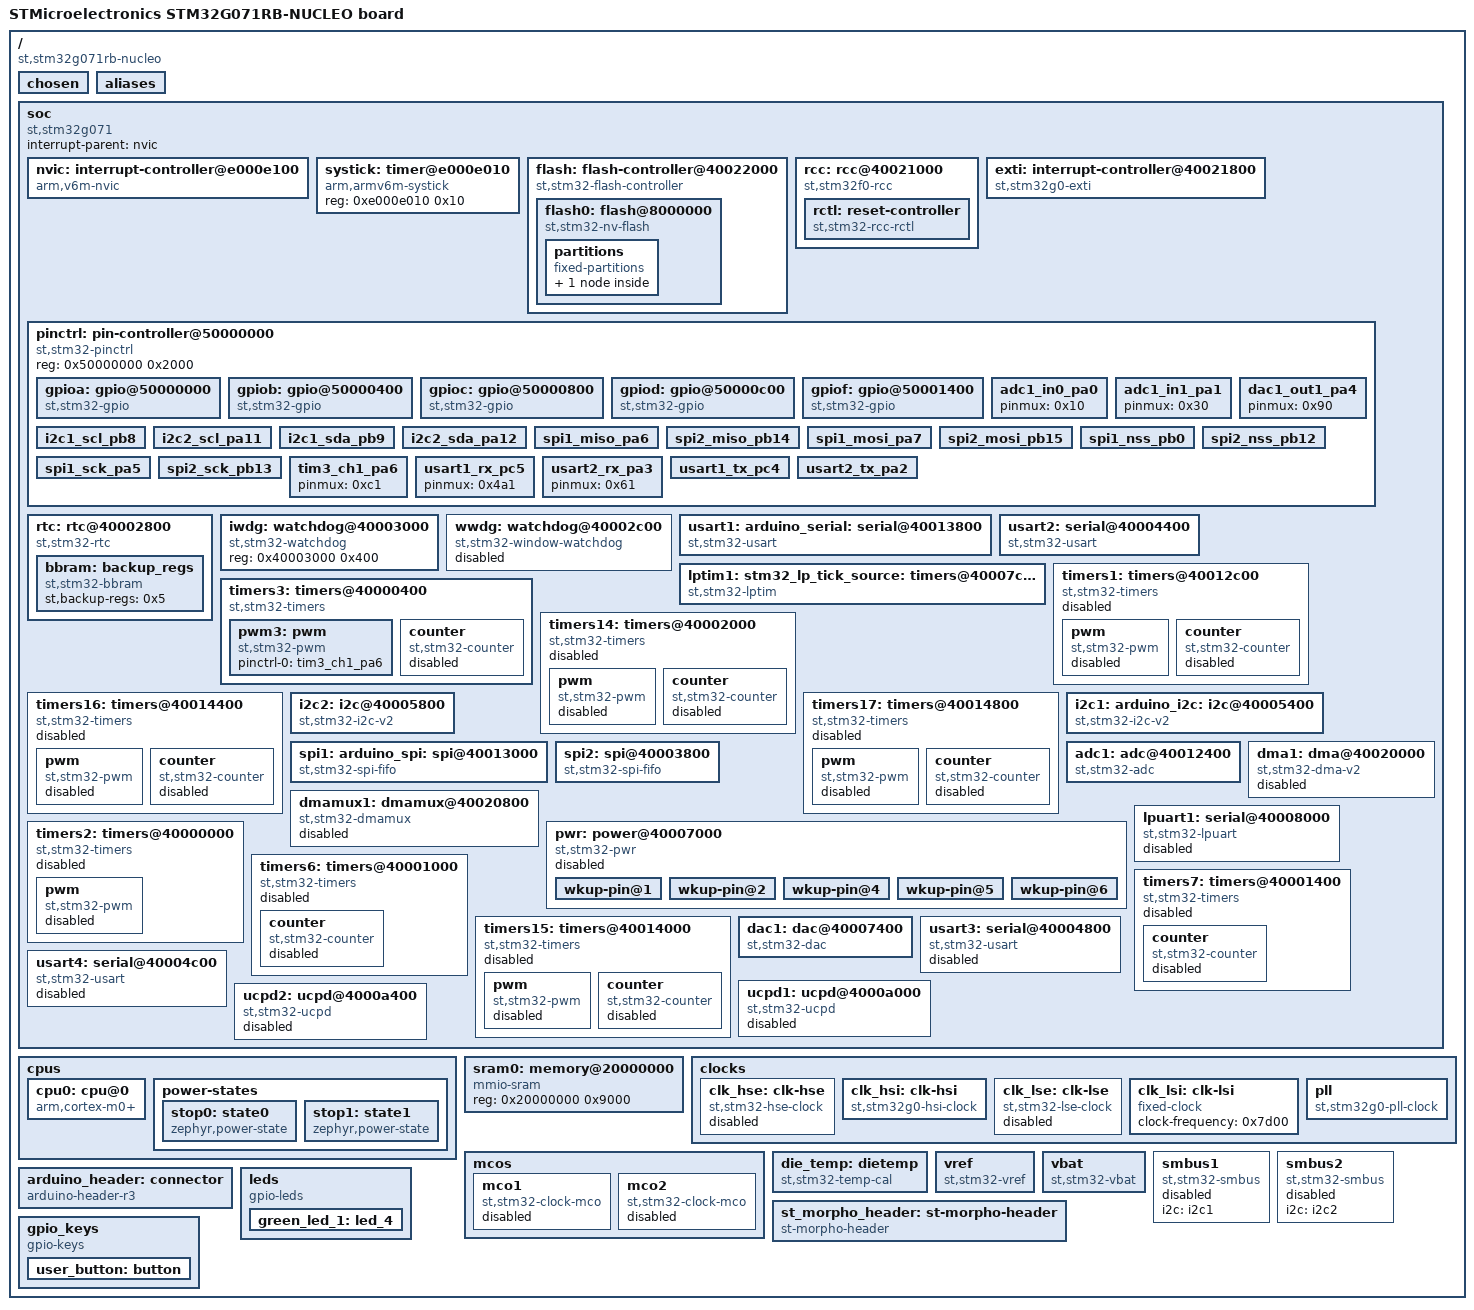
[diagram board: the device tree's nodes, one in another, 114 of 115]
/dts-v1/;

/* node '/' defined in zephyr\dts\common\skeleton.dtsi:9 */
/ {
	#address-cells = < 0x1 >;                              /* in zephyr\dts\common\skeleton.dtsi:10 */
	#size-cells = < 0x1 >;                                 /* in zephyr\dts\common\skeleton.dtsi:11 */
	model = "STMicroelectronics STM32G071RB-NUCLEO board"; /* in zephyr\boards\st\nucleo_g071rb\nucleo_g071rb.dts:16 */
	compatible = "st,stm32g071rb-nucleo";                  /* in zephyr\boards\st\nucleo_g071rb\nucleo_g071rb.dts:17 */

	/* node '/chosen' defined in zephyr\dts\common\skeleton.dtsi:13 */
	chosen {
		zephyr,flash-controller = &flash; /* in zephyr\dts\arm\st\g0\stm32g0.dtsi:26 */
		zephyr,console = &usart2;         /* in zephyr\boards\st\nucleo_g071rb\nucleo_g071rb.dts:20 */
		zephyr,shell-uart = &usart2;      /* in zephyr\boards\st\nucleo_g071rb\nucleo_g071rb.dts:21 */
		zephyr,sram = &sram0;             /* in zephyr\boards\st\nucleo_g071rb\nucleo_g071rb.dts:22 */
		zephyr,flash = &flash0;           /* in zephyr\boards\st\nucleo_g071rb\nucleo_g071rb.dts:23 */
	};

	/* node '/aliases' defined in zephyr\dts\common\skeleton.dtsi:15 */
	aliases {
		led0 = &green_led_1;   /* in zephyr\boards\st\nucleo_g071rb\nucleo_g071rb.dts:46 */
		sw0 = &user_button;    /* in zephyr\boards\st\nucleo_g071rb\nucleo_g071rb.dts:47 */
		watchdog0 = &iwdg;     /* in zephyr\boards\st\nucleo_g071rb\nucleo_g071rb.dts:48 */
		die-temp0 = &die_temp; /* in zephyr\boards\st\nucleo_g071rb\nucleo_g071rb.dts:49 */
		volt-sensor0 = &vref;  /* in zephyr\boards\st\nucleo_g071rb\nucleo_g071rb.dts:50 */
		volt-sensor1 = &vbat;  /* in zephyr\boards\st\nucleo_g071rb\nucleo_g071rb.dts:51 */
	};

	/* node '/soc' defined in zephyr\dts\arm\armv6-m.dtsi:6 */
	soc {
		#address-cells = < 0x1 >;     /* in zephyr\dts\arm\armv6-m.dtsi:7 */
		#size-cells = < 0x1 >;        /* in zephyr\dts\arm\armv6-m.dtsi:8 */
		interrupt-parent = < &nvic >; /* in zephyr\dts\arm\armv6-m.dtsi:10 */
		ranges;                       /* in zephyr\dts\arm\armv6-m.dtsi:11 */
		compatible = "st,stm32g071",
		             "st,stm32g0",
		             "simple-bus";    /* in zephyr\dts\arm\st\g0\stm32g071.dtsi:13 */

		/* node '/soc/interrupt-controller@e000e100' defined in zephyr\dts\arm\armv6-m.dtsi:13 */
		nvic: interrupt-controller@e000e100 {
			#address-cells = < 0x1 >;            /* in zephyr\dts\arm\armv6-m.dtsi:14 */
			compatible = "arm,v6m-nvic";         /* in zephyr\dts\arm\armv6-m.dtsi:15 */
			reg = < 0xe000e100 0xc00 >;          /* in zephyr\dts\arm\armv6-m.dtsi:16 */
			interrupt-controller;                /* in zephyr\dts\arm\armv6-m.dtsi:17 */
			#interrupt-cells = < 0x2 >;          /* in zephyr\dts\arm\armv6-m.dtsi:18 */
			arm,num-irq-priority-bits = < 0x2 >; /* in zephyr\dts\arm\st\g0\stm32g0.dtsi:558 */
			phandle = < 0x1 >;                   /* in zephyr\dts\arm\armv6-m.dtsi:10 */
		};

		/* node '/soc/timer@e000e010' defined in zephyr\dts\arm\armv6-m.dtsi:21 */
		systick: timer@e000e010 {
			compatible = "arm,armv6m-systick"; /* in zephyr\dts\arm\armv6-m.dtsi:22 */
			reg = < 0xe000e010 0x10 >;         /* in zephyr\dts\arm\armv6-m.dtsi:23 */
		};

		/* node '/soc/flash-controller@40022000' defined in zephyr\dts\arm\st\g0\stm32g0.dtsi:111 */
		flash: flash-controller@40022000 {
			compatible = "st,stm32-flash-controller",
			             "st,stm32g0-flash-controller"; /* in zephyr\dts\arm\st\g0\stm32g0.dtsi:112 */
			reg = < 0x40022000 0x400 >;                 /* in zephyr\dts\arm\st\g0\stm32g0.dtsi:113 */
			interrupts = < 0x3 0x0 >;                   /* in zephyr\dts\arm\st\g0\stm32g0.dtsi:114 */
			clocks = < &rcc 0x38 0x100 >;               /* in zephyr\dts\arm\st\g0\stm32g0.dtsi:115 */
			#address-cells = < 0x1 >;                   /* in zephyr\dts\arm\st\g0\stm32g0.dtsi:117 */
			#size-cells = < 0x1 >;                      /* in zephyr\dts\arm\st\g0\stm32g0.dtsi:118 */

			/* node '/soc/flash-controller@40022000/flash@8000000' defined in zephyr\dts\arm\st\g0\stm32g0.dtsi:120 */
			flash0: flash@8000000 {
				compatible = "st,stm32-nv-flash",
				             "soc-nv-flash";      /* in zephyr\dts\arm\st\g0\stm32g0.dtsi:121 */
				write-block-size = < 0x8 >;       /* in zephyr\dts\arm\st\g0\stm32g0.dtsi:123 */
				erase-block-size = < 0x800 >;     /* in zephyr\dts\arm\st\g0\stm32g0.dtsi:124 */
				max-erase-time = < 0x28 >;        /* in zephyr\dts\arm\st\g0\stm32g0.dtsi:126 */
				reg = < 0x8000000 0x20000 >;      /* in zephyr\dts\arm\st\g0\stm32g071Xb.dtsi:19 */

				/* node '/soc/flash-controller@40022000/flash@8000000/partitions' defined in zephyr\boards\st\nucleo_g071rb\nucleo_g071rb.dts:169 */
				partitions {
					compatible = "fixed-partitions"; /* in zephyr\boards\st\nucleo_g071rb\nucleo_g071rb.dts:170 */
					#address-cells = < 0x1 >;        /* in zephyr\boards\st\nucleo_g071rb\nucleo_g071rb.dts:171 */
					#size-cells = < 0x1 >;           /* in zephyr\boards\st\nucleo_g071rb\nucleo_g071rb.dts:172 */

					/* node '/soc/flash-controller@40022000/flash@8000000/partitions/partition@1f000' defined in zephyr\boards\st\nucleo_g071rb\nucleo_g071rb.dts:175 */
					storage_partition: partition@1f000 {
						label = "storage";        /* in zephyr\boards\st\nucleo_g071rb\nucleo_g071rb.dts:176 */
						reg = < 0x1f000 0x1000 >; /* in zephyr\boards\st\nucleo_g071rb\nucleo_g071rb.dts:177 */
					};
				};
			};
		};

		/* node '/soc/rcc@40021000' defined in zephyr\dts\arm\st\g0\stm32g0.dtsi:130 */
		rcc: rcc@40021000 {
			compatible = "st,stm32f0-rcc";   /* in zephyr\dts\arm\st\g0\stm32g0.dtsi:131 */
			#clock-cells = < 0x2 >;          /* in zephyr\dts\arm\st\g0\stm32g0.dtsi:132 */
			reg = < 0x40021000 0x400 >;      /* in zephyr\dts\arm\st\g0\stm32g0.dtsi:133 */
			clocks = < &pll >;               /* in zephyr\boards\st\nucleo_g071rb\nucleo_g071rb.dts:74 */
			clock-frequency = < 0x3d09000 >; /* in zephyr\boards\st\nucleo_g071rb\nucleo_g071rb.dts:75 */
			ahb-prescaler = < 0x1 >;         /* in zephyr\boards\st\nucleo_g071rb\nucleo_g071rb.dts:76 */
			apb1-prescaler = < 0x1 >;        /* in zephyr\boards\st\nucleo_g071rb\nucleo_g071rb.dts:77 */
			phandle = < 0x2 >;               /* in zephyr\dts\arm\st\g0\stm32g0.dtsi:115 */

			/* node '/soc/rcc@40021000/reset-controller' defined in zephyr\dts\arm\st\g0\stm32g0.dtsi:135 */
			rctl: reset-controller {
				compatible = "st,stm32-rcc-rctl"; /* in zephyr\dts\arm\st\g0\stm32g0.dtsi:136 */
				#reset-cells = < 0x1 >;           /* in zephyr\dts\arm\st\g0\stm32g0.dtsi:137 */
				phandle = < 0x4 >;                /* in zephyr\dts\arm\st\g0\stm32g0.dtsi:242 */
			};
		};

		/* node '/soc/interrupt-controller@40021800' defined in zephyr\dts\arm\st\g0\stm32g0.dtsi:141 */
		exti: interrupt-controller@40021800 {
			compatible = "st,stm32g0-exti",
			             "st,stm32-exti";   /* in zephyr\dts\arm\st\g0\stm32g0.dtsi:142 */
			interrupt-controller;           /* in zephyr\dts\arm\st\g0\stm32g0.dtsi:143 */
			#interrupt-cells = < 0x1 >;     /* in zephyr\dts\arm\st\g0\stm32g0.dtsi:144 */
			#address-cells = < 0x1 >;       /* in zephyr\dts\arm\st\g0\stm32g0.dtsi:145 */
			reg = < 0x40021800 0x400 >;     /* in zephyr\dts\arm\st\g0\stm32g0.dtsi:146 */
			clocks = < &rcc 0x40 0x1 >;     /* in zephyr\dts\arm\st\g0\stm32g0.dtsi:147 */
			num-lines = < 0x20 >;           /* in zephyr\dts\arm\st\g0\stm32g0.dtsi:148 */
			interrupts = < 0x5 0x0 >,
			             < 0x6 0x0 >,
			             < 0x7 0x0 >;       /* in zephyr\dts\arm\st\g0\stm32g0.dtsi:149 */
			interrupt-names = "line0-1",
			                  "line2-3",
			                  "line4-15";   /* in zephyr\dts\arm\st\g0\stm32g0.dtsi:150 */
			line-ranges = < 0x0 0x2 >,
			              < 0x2 0x2 >,
			              < 0x4 0xc >;      /* in zephyr\dts\arm\st\g0\stm32g0.dtsi:151 */
		};

		/* node '/soc/pin-controller@50000000' defined in zephyr\dts\arm\st\g0\stm32g0.dtsi:154 */
		pinctrl: pin-controller@50000000 {
			compatible = "st,stm32-pinctrl"; /* in zephyr\dts\arm\st\g0\stm32g0.dtsi:155 */
			#address-cells = < 0x1 >;        /* in zephyr\dts\arm\st\g0\stm32g0.dtsi:156 */
			#size-cells = < 0x1 >;           /* in zephyr\dts\arm\st\g0\stm32g0.dtsi:157 */
			reg = < 0x50000000 0x2000 >;     /* in zephyr\dts\arm\st\g0\stm32g0.dtsi:158 */

			/* node '/soc/pin-controller@50000000/gpio@50000000' defined in zephyr\dts\arm\st\g0\stm32g0.dtsi:160 */
			gpioa: gpio@50000000 {
				compatible = "st,stm32-gpio"; /* in zephyr\dts\arm\st\g0\stm32g0.dtsi:161 */
				gpio-controller;              /* in zephyr\dts\arm\st\g0\stm32g0.dtsi:162 */
				#gpio-cells = < 0x2 >;        /* in zephyr\dts\arm\st\g0\stm32g0.dtsi:163 */
				reg = < 0x50000000 0x400 >;   /* in zephyr\dts\arm\st\g0\stm32g0.dtsi:164 */
				clocks = < &rcc 0x34 0x1 >;   /* in zephyr\dts\arm\st\g0\stm32g0.dtsi:165 */
				phandle = < 0x18 >;           /* in zephyr\dts\arm\st\g0\stm32g0.dtsi:486 */
			};

			/* node '/soc/pin-controller@50000000/gpio@50000400' defined in zephyr\dts\arm\st\g0\stm32g0.dtsi:168 */
			gpiob: gpio@50000400 {
				compatible = "st,stm32-gpio"; /* in zephyr\dts\arm\st\g0\stm32g0.dtsi:169 */
				gpio-controller;              /* in zephyr\dts\arm\st\g0\stm32g0.dtsi:170 */
				#gpio-cells = < 0x2 >;        /* in zephyr\dts\arm\st\g0\stm32g0.dtsi:171 */
				reg = < 0x50000400 0x400 >;   /* in zephyr\dts\arm\st\g0\stm32g0.dtsi:172 */
				clocks = < &rcc 0x34 0x2 >;   /* in zephyr\dts\arm\st\g0\stm32g0.dtsi:173 */
				phandle = < 0x1a >;           /* in zephyr\dts\arm\st\g0\stm32g0.dtsi:509 */
			};

			/* node '/soc/pin-controller@50000000/gpio@50000800' defined in zephyr\dts\arm\st\g0\stm32g0.dtsi:176 */
			gpioc: gpio@50000800 {
				compatible = "st,stm32-gpio"; /* in zephyr\dts\arm\st\g0\stm32g0.dtsi:177 */
				gpio-controller;              /* in zephyr\dts\arm\st\g0\stm32g0.dtsi:178 */
				#gpio-cells = < 0x2 >;        /* in zephyr\dts\arm\st\g0\stm32g0.dtsi:179 */
				reg = < 0x50000800 0x400 >;   /* in zephyr\dts\arm\st\g0\stm32g0.dtsi:180 */
				clocks = < &rcc 0x34 0x4 >;   /* in zephyr\dts\arm\st\g0\stm32g0.dtsi:181 */
				phandle = < 0x19 >;           /* in zephyr\dts\arm\st\g0\stm32g0.dtsi:491 */
			};

			/* node '/soc/pin-controller@50000000/gpio@50000c00' defined in zephyr\dts\arm\st\g0\stm32g0.dtsi:184 */
			gpiod: gpio@50000c00 {
				compatible = "st,stm32-gpio"; /* in zephyr\dts\arm\st\g0\stm32g0.dtsi:185 */
				gpio-controller;              /* in zephyr\dts\arm\st\g0\stm32g0.dtsi:186 */
				#gpio-cells = < 0x2 >;        /* in zephyr\dts\arm\st\g0\stm32g0.dtsi:187 */
				reg = < 0x50000c00 0x400 >;   /* in zephyr\dts\arm\st\g0\stm32g0.dtsi:188 */
				clocks = < &rcc 0x34 0x8 >;   /* in zephyr\dts\arm\st\g0\stm32g0.dtsi:189 */
				phandle = < 0x22 >;           /* in zephyr\boards\st\nucleo_g071rb\st_morpho_connector.dtsi:15 */
			};

			/* node '/soc/pin-controller@50000000/gpio@50001400' defined in zephyr\dts\arm\st\g0\stm32g0.dtsi:192 */
			gpiof: gpio@50001400 {
				compatible = "st,stm32-gpio"; /* in zephyr\dts\arm\st\g0\stm32g0.dtsi:193 */
				gpio-controller;              /* in zephyr\dts\arm\st\g0\stm32g0.dtsi:194 */
				#gpio-cells = < 0x2 >;        /* in zephyr\dts\arm\st\g0\stm32g0.dtsi:195 */
				reg = < 0x50001400 0x400 >;   /* in zephyr\dts\arm\st\g0\stm32g0.dtsi:196 */
				clocks = < &rcc 0x34 0x20 >;  /* in zephyr\dts\arm\st\g0\stm32g0.dtsi:197 */
				phandle = < 0x23 >;           /* in zephyr\boards\st\nucleo_g071rb\st_morpho_connector.dtsi:15 */
			};

			/* node '/soc/pin-controller@50000000/adc1_in0_pa0' defined in modules\hal\stm32\dts\st\g0\stm32g071r(6-8-b)tx-pinctrl.dtsi:15 */
			adc1_in0_pa0: adc1_in0_pa0 {
				pinmux = < 0x10 >;  /* in modules\hal\stm32\dts\st\g0\stm32g071r(6-8-b)tx-pinctrl.dtsi:16 */
				phandle = < 0x16 >; /* in zephyr\boards\st\nucleo_g071rb\nucleo_g071rb.dts:150 */
			};

			/* node '/soc/pin-controller@50000000/adc1_in1_pa1' defined in modules\hal\stm32\dts\st\g0\stm32g071r(6-8-b)tx-pinctrl.dtsi:19 */
			adc1_in1_pa1: adc1_in1_pa1 {
				pinmux = < 0x30 >;  /* in modules\hal\stm32\dts\st\g0\stm32g071r(6-8-b)tx-pinctrl.dtsi:20 */
				phandle = < 0x17 >; /* in zephyr\boards\st\nucleo_g071rb\nucleo_g071rb.dts:150 */
			};

			/* node '/soc/pin-controller@50000000/dac1_out1_pa4' defined in modules\hal\stm32\dts\st\g0\stm32g071r(6-8-b)tx-pinctrl.dtsi:415 */
			dac1_out1_pa4: dac1_out1_pa4 {
				pinmux = < 0x90 >;  /* in modules\hal\stm32\dts\st\g0\stm32g071r(6-8-b)tx-pinctrl.dtsi:416 */
				phandle = < 0x1b >; /* in zephyr\boards\st\nucleo_g071rb\nucleo_g071rb.dts:160 */
			};

			/* node '/soc/pin-controller@50000000/i2c1_scl_pb8' defined in modules\hal\stm32\dts\st\g0\stm32g071r(6-8-b)tx-pinctrl.dtsi:437 */
			i2c1_scl_pb8: i2c1_scl_pb8 {
				pinmux = < 0x306 >; /* in modules\hal\stm32\dts\st\g0\stm32g071r(6-8-b)tx-pinctrl.dtsi:438 */
				bias-pull-up;       /* in modules\hal\stm32\dts\st\g0\stm32g071r(6-8-b)tx-pinctrl.dtsi:439 */
				drive-open-drain;   /* in modules\hal\stm32\dts\st\g0\stm32g071r(6-8-b)tx-pinctrl.dtsi:440 */
				phandle = < 0xa >;  /* in zephyr\boards\st\nucleo_g071rb\nucleo_g071rb.dts:120 */
			};

			/* node '/soc/pin-controller@50000000/i2c2_scl_pa11' defined in modules\hal\stm32\dts\st\g0\stm32g071r(6-8-b)tx-pinctrl.dtsi:443 */
			i2c2_scl_pa11: i2c2_scl_pa11 {
				pinmux = < 0x166 >; /* in modules\hal\stm32\dts\st\g0\stm32g071r(6-8-b)tx-pinctrl.dtsi:444 */
				bias-pull-up;       /* in modules\hal\stm32\dts\st\g0\stm32g071r(6-8-b)tx-pinctrl.dtsi:445 */
				drive-open-drain;   /* in modules\hal\stm32\dts\st\g0\stm32g071r(6-8-b)tx-pinctrl.dtsi:446 */
				phandle = < 0xc >;  /* in zephyr\boards\st\nucleo_g071rb\nucleo_g071rb.dts:127 */
			};

			/* node '/soc/pin-controller@50000000/i2c1_sda_pb9' defined in modules\hal\stm32\dts\st\g0\stm32g071r(6-8-b)tx-pinctrl.dtsi:475 */
			i2c1_sda_pb9: i2c1_sda_pb9 {
				pinmux = < 0x326 >; /* in modules\hal\stm32\dts\st\g0\stm32g071r(6-8-b)tx-pinctrl.dtsi:476 */
				bias-pull-up;       /* in modules\hal\stm32\dts\st\g0\stm32g071r(6-8-b)tx-pinctrl.dtsi:477 */
				drive-open-drain;   /* in modules\hal\stm32\dts\st\g0\stm32g071r(6-8-b)tx-pinctrl.dtsi:478 */
				phandle = < 0xb >;  /* in zephyr\boards\st\nucleo_g071rb\nucleo_g071rb.dts:120 */
			};

			/* node '/soc/pin-controller@50000000/i2c2_sda_pa12' defined in modules\hal\stm32\dts\st\g0\stm32g071r(6-8-b)tx-pinctrl.dtsi:481 */
			i2c2_sda_pa12: i2c2_sda_pa12 {
				pinmux = < 0x186 >; /* in modules\hal\stm32\dts\st\g0\stm32g071r(6-8-b)tx-pinctrl.dtsi:482 */
				bias-pull-up;       /* in modules\hal\stm32\dts\st\g0\stm32g071r(6-8-b)tx-pinctrl.dtsi:483 */
				drive-open-drain;   /* in modules\hal\stm32\dts\st\g0\stm32g071r(6-8-b)tx-pinctrl.dtsi:484 */
				phandle = < 0xd >;  /* in zephyr\boards\st\nucleo_g071rb\nucleo_g071rb.dts:127 */
			};

			/* node '/soc/pin-controller@50000000/spi1_miso_pa6' defined in modules\hal\stm32\dts\st\g0\stm32g071r(6-8-b)tx-pinctrl.dtsi:624 */
			spi1_miso_pa6: spi1_miso_pa6 {
				pinmux = < 0xc0 >;  /* in modules\hal\stm32\dts\st\g0\stm32g071r(6-8-b)tx-pinctrl.dtsi:625 */
				bias-pull-down;     /* in modules\hal\stm32\dts\st\g0\stm32g071r(6-8-b)tx-pinctrl.dtsi:626 */
				phandle = < 0x10 >; /* in zephyr\boards\st\nucleo_g071rb\nucleo_g071rb.dts:134 */
			};

			/* node '/soc/pin-controller@50000000/spi2_miso_pb14' defined in modules\hal\stm32\dts\st\g0\stm32g071r(6-8-b)tx-pinctrl.dtsi:664 */
			spi2_miso_pb14: spi2_miso_pb14 {
				pinmux = < 0x3c0 >; /* in modules\hal\stm32\dts\st\g0\stm32g071r(6-8-b)tx-pinctrl.dtsi:665 */
				bias-pull-down;     /* in modules\hal\stm32\dts\st\g0\stm32g071r(6-8-b)tx-pinctrl.dtsi:666 */
				phandle = < 0x14 >; /* in zephyr\boards\st\nucleo_g071rb\nucleo_g071rb.dts:141 */
			};

			/* node '/soc/pin-controller@50000000/spi1_mosi_pa7' defined in modules\hal\stm32\dts\st\g0\stm32g071r(6-8-b)tx-pinctrl.dtsi:686 */
			spi1_mosi_pa7: spi1_mosi_pa7 {
				pinmux = < 0xe0 >;  /* in modules\hal\stm32\dts\st\g0\stm32g071r(6-8-b)tx-pinctrl.dtsi:687 */
				bias-pull-down;     /* in modules\hal\stm32\dts\st\g0\stm32g071r(6-8-b)tx-pinctrl.dtsi:688 */
				phandle = < 0x11 >; /* in zephyr\boards\st\nucleo_g071rb\nucleo_g071rb.dts:134 */
			};

			/* node '/soc/pin-controller@50000000/spi2_mosi_pb15' defined in modules\hal\stm32\dts\st\g0\stm32g071r(6-8-b)tx-pinctrl.dtsi:726 */
			spi2_mosi_pb15: spi2_mosi_pb15 {
				pinmux = < 0x3e0 >; /* in modules\hal\stm32\dts\st\g0\stm32g071r(6-8-b)tx-pinctrl.dtsi:727 */
				bias-pull-down;     /* in modules\hal\stm32\dts\st\g0\stm32g071r(6-8-b)tx-pinctrl.dtsi:728 */
				phandle = < 0x15 >; /* in zephyr\boards\st\nucleo_g071rb\nucleo_g071rb.dts:141 */
			};

			/* node '/soc/pin-controller@50000000/spi1_nss_pb0' defined in modules\hal\stm32\dts\st\g0\stm32g071r(6-8-b)tx-pinctrl.dtsi:753 */
			spi1_nss_pb0: spi1_nss_pb0 {
				pinmux = < 0x200 >; /* in modules\hal\stm32\dts\st\g0\stm32g071r(6-8-b)tx-pinctrl.dtsi:754 */
				bias-pull-up;       /* in modules\hal\stm32\dts\st\g0\stm32g071r(6-8-b)tx-pinctrl.dtsi:755 */
				phandle = < 0xe >;  /* in zephyr\boards\st\nucleo_g071rb\nucleo_g071rb.dts:134 */
			};

			/* node '/soc/pin-controller@50000000/spi2_nss_pb12' defined in modules\hal\stm32\dts\st\g0\stm32g071r(6-8-b)tx-pinctrl.dtsi:773 */
			spi2_nss_pb12: spi2_nss_pb12 {
				pinmux = < 0x380 >; /* in modules\hal\stm32\dts\st\g0\stm32g071r(6-8-b)tx-pinctrl.dtsi:774 */
				bias-pull-up;       /* in modules\hal\stm32\dts\st\g0\stm32g071r(6-8-b)tx-pinctrl.dtsi:775 */
				phandle = < 0x12 >; /* in zephyr\boards\st\nucleo_g071rb\nucleo_g071rb.dts:141 */
			};

			/* node '/soc/pin-controller@50000000/spi1_sck_pa5' defined in modules\hal\stm32\dts\st\g0\stm32g071r(6-8-b)tx-pinctrl.dtsi:791 */
			spi1_sck_pa5: spi1_sck_pa5 {
				pinmux = < 0xa0 >;             /* in modules\hal\stm32\dts\st\g0\stm32g071r(6-8-b)tx-pinctrl.dtsi:792 */
				bias-pull-down;                /* in modules\hal\stm32\dts\st\g0\stm32g071r(6-8-b)tx-pinctrl.dtsi:793 */
				slew-rate = "very-high-speed"; /* in modules\hal\stm32\dts\st\g0\stm32g071r(6-8-b)tx-pinctrl.dtsi:794 */
				phandle = < 0xf >;             /* in zephyr\boards\st\nucleo_g071rb\nucleo_g071rb.dts:134 */
			};

			/* node '/soc/pin-controller@50000000/spi2_sck_pb13' defined in modules\hal\stm32\dts\st\g0\stm32g071r(6-8-b)tx-pinctrl.dtsi:827 */
			spi2_sck_pb13: spi2_sck_pb13 {
				pinmux = < 0x3a0 >;            /* in modules\hal\stm32\dts\st\g0\stm32g071r(6-8-b)tx-pinctrl.dtsi:828 */
				bias-pull-down;                /* in modules\hal\stm32\dts\st\g0\stm32g071r(6-8-b)tx-pinctrl.dtsi:829 */
				slew-rate = "very-high-speed"; /* in modules\hal\stm32\dts\st\g0\stm32g071r(6-8-b)tx-pinctrl.dtsi:830 */
				phandle = < 0x13 >;            /* in zephyr\boards\st\nucleo_g071rb\nucleo_g071rb.dts:141 */
			};

			/* node '/soc/pin-controller@50000000/tim3_ch1_pa6' defined in modules\hal\stm32\dts\st\g0\stm32g071r(6-8-b)tx-pinctrl.dtsi:969 */
			tim3_ch1_pa6: tim3_ch1_pa6 {
				pinmux = < 0xc1 >; /* in modules\hal\stm32\dts\st\g0\stm32g071r(6-8-b)tx-pinctrl.dtsi:970 */
				phandle = < 0x9 >; /* in zephyr\boards\st\nucleo_g071rb\nucleo_g071rb.dts:114 */
			};

			/* node '/soc/pin-controller@50000000/usart1_rx_pc5' defined in modules\hal\stm32\dts\st\g0\stm32g071r(6-8-b)tx-pinctrl.dtsi:1284 */
			usart1_rx_pc5: usart1_rx_pc5 {
				pinmux = < 0x4a1 >; /* in modules\hal\stm32\dts\st\g0\stm32g071r(6-8-b)tx-pinctrl.dtsi:1285 */
				phandle = < 0x6 >;  /* in zephyr\boards\st\nucleo_g071rb\nucleo_g071rb.dts:81 */
			};

			/* node '/soc/pin-controller@50000000/usart2_rx_pa3' defined in modules\hal\stm32\dts\st\g0\stm32g071r(6-8-b)tx-pinctrl.dtsi:1288 */
			usart2_rx_pa3: usart2_rx_pa3 {
				pinmux = < 0x61 >; /* in modules\hal\stm32\dts\st\g0\stm32g071r(6-8-b)tx-pinctrl.dtsi:1289 */
				phandle = < 0x8 >; /* in zephyr\boards\st\nucleo_g071rb\nucleo_g071rb.dts:88 */
			};

			/* node '/soc/pin-controller@50000000/usart1_tx_pc4' defined in modules\hal\stm32\dts\st\g0\stm32g071r(6-8-b)tx-pinctrl.dtsi:1359 */
			usart1_tx_pc4: usart1_tx_pc4 {
				pinmux = < 0x481 >; /* in modules\hal\stm32\dts\st\g0\stm32g071r(6-8-b)tx-pinctrl.dtsi:1360 */
				bias-pull-up;       /* in modules\hal\stm32\dts\st\g0\stm32g071r(6-8-b)tx-pinctrl.dtsi:1361 */
				phandle = < 0x5 >;  /* in zephyr\boards\st\nucleo_g071rb\nucleo_g071rb.dts:81 */
			};

			/* node '/soc/pin-controller@50000000/usart2_tx_pa2' defined in modules\hal\stm32\dts\st\g0\stm32g071r(6-8-b)tx-pinctrl.dtsi:1364 */
			usart2_tx_pa2: usart2_tx_pa2 {
				pinmux = < 0x41 >; /* in modules\hal\stm32\dts\st\g0\stm32g071r(6-8-b)tx-pinctrl.dtsi:1365 */
				bias-pull-up;      /* in modules\hal\stm32\dts\st\g0\stm32g071r(6-8-b)tx-pinctrl.dtsi:1366 */
				phandle = < 0x7 >; /* in zephyr\boards\st\nucleo_g071rb\nucleo_g071rb.dts:88 */
			};
		};

		/* node '/soc/rtc@40002800' defined in zephyr\dts\arm\st\g0\stm32g0.dtsi:201 */
		rtc: rtc@40002800 {
			compatible = "st,stm32-rtc";      /* in zephyr\dts\arm\st\g0\stm32g0.dtsi:202 */
			reg = < 0x40002800 0x400 >;       /* in zephyr\dts\arm\st\g0\stm32g0.dtsi:203 */
			interrupts = < 0x2 0x0 >;         /* in zephyr\dts\arm\st\g0\stm32g0.dtsi:204 */
			prescaler = < 0x8000 >;           /* in zephyr\dts\arm\st\g0\stm32g0.dtsi:206 */
			alarms-count = < 0x2 >;           /* in zephyr\dts\arm\st\g0\stm32g0.dtsi:207 */
			alrm-exti-line = < 0x13 >;        /* in zephyr\dts\arm\st\g0\stm32g0.dtsi:208 */
			clocks = < &rcc 0x3c 0x400 >,
			         < &rcc 0x3 0x10c8005c >; /* in zephyr\boards\st\nucleo_g071rb\nucleo_g071rb.dts:95 */
			status = "okay";                  /* in zephyr\boards\st\nucleo_g071rb\nucleo_g071rb.dts:97 */

			/* node '/soc/rtc@40002800/backup_regs' defined in zephyr\dts\arm\st\g0\stm32g0.dtsi:217 */
			bbram: backup_regs {
				compatible = "st,stm32-bbram"; /* in zephyr\dts\arm\st\g0\stm32g0.dtsi:218 */
				st,backup-regs = < 0x5 >;      /* in zephyr\dts\arm\st\g0\stm32g0.dtsi:219 */
				status = "okay";               /* in zephyr\boards\st\nucleo_g071rb\nucleo_g071rb.dts:100 */
			};
		};

		/* node '/soc/watchdog@40003000' defined in zephyr\dts\arm\st\g0\stm32g0.dtsi:224 */
		iwdg: watchdog@40003000 {
			compatible = "st,stm32-watchdog"; /* in zephyr\dts\arm\st\g0\stm32g0.dtsi:225 */
			reg = < 0x40003000 0x400 >;       /* in zephyr\dts\arm\st\g0\stm32g0.dtsi:226 */
			status = "okay";                  /* in zephyr\boards\st\nucleo_g071rb\nucleo_g071rb.dts:105 */
		};

		/* node '/soc/watchdog@40002c00' defined in zephyr\dts\arm\st\g0\stm32g0.dtsi:230 */
		wwdg: watchdog@40002c00 {
			compatible = "st,stm32-window-watchdog"; /* in zephyr\dts\arm\st\g0\stm32g0.dtsi:231 */
			reg = < 0x40002c00 0x400 >;              /* in zephyr\dts\arm\st\g0\stm32g0.dtsi:232 */
			clocks = < &rcc 0x3c 0x800 >;            /* in zephyr\dts\arm\st\g0\stm32g0.dtsi:233 */
			interrupts = < 0x0 0x2 >;                /* in zephyr\dts\arm\st\g0\stm32g0.dtsi:234 */
			status = "disabled";                     /* in zephyr\dts\arm\st\g0\stm32g0.dtsi:235 */
		};

		/* node '/soc/serial@40013800' defined in zephyr\dts\arm\st\g0\stm32g0.dtsi:238 */
		usart1: arduino_serial: serial@40013800 {
			compatible = "st,stm32-usart",
			             "st,stm32-uart";                  /* in zephyr\dts\arm\st\g0\stm32g0.dtsi:239 */
			reg = < 0x40013800 0x400 >;                    /* in zephyr\dts\arm\st\g0\stm32g0.dtsi:240 */
			clocks = < &rcc 0x40 0x4000 >;                 /* in zephyr\dts\arm\st\g0\stm32g0.dtsi:241 */
			resets = < &rctl 0x60e >;                      /* in zephyr\dts\arm\st\g0\stm32g0.dtsi:242 */
			interrupts = < 0x1b 0x0 >;                     /* in zephyr\dts\arm\st\g0\stm32g0.dtsi:243 */
			pinctrl-0 = < &usart1_tx_pc4 &usart1_rx_pc5 >; /* in zephyr\boards\st\nucleo_g071rb\nucleo_g071rb.dts:81 */
			pinctrl-names = "default";                     /* in zephyr\boards\st\nucleo_g071rb\nucleo_g071rb.dts:82 */
			current-speed = < 0x1c200 >;                   /* in zephyr\boards\st\nucleo_g071rb\nucleo_g071rb.dts:83 */
			status = "okay";                               /* in zephyr\boards\st\nucleo_g071rb\nucleo_g071rb.dts:84 */
		};

		/* node '/soc/serial@40004400' defined in zephyr\dts\arm\st\g0\stm32g0.dtsi:247 */
		usart2: serial@40004400 {
			compatible = "st,stm32-usart",
			             "st,stm32-uart";                  /* in zephyr\dts\arm\st\g0\stm32g0.dtsi:248 */
			reg = < 0x40004400 0x400 >;                    /* in zephyr\dts\arm\st\g0\stm32g0.dtsi:249 */
			clocks = < &rcc 0x3c 0x20000 >;                /* in zephyr\dts\arm\st\g0\stm32g0.dtsi:250 */
			resets = < &rctl 0x591 >;                      /* in zephyr\dts\arm\st\g0\stm32g0.dtsi:251 */
			interrupts = < 0x1c 0x0 >;                     /* in zephyr\dts\arm\st\g0\stm32g0.dtsi:252 */
			pinctrl-0 = < &usart2_tx_pa2 &usart2_rx_pa3 >; /* in zephyr\boards\st\nucleo_g071rb\nucleo_g071rb.dts:88 */
			pinctrl-names = "default";                     /* in zephyr\boards\st\nucleo_g071rb\nucleo_g071rb.dts:89 */
			current-speed = < 0x1c200 >;                   /* in zephyr\boards\st\nucleo_g071rb\nucleo_g071rb.dts:90 */
			status = "okay";                               /* in zephyr\boards\st\nucleo_g071rb\nucleo_g071rb.dts:91 */
		};

		/* node '/soc/timers@40007c00' defined in zephyr\dts\arm\st\g0\stm32g0.dtsi:256 */
		lptim1: stm32_lp_tick_source: timers@40007c00 {
			compatible = "st,stm32-lptim";     /* in zephyr\dts\arm\st\g0\stm32g0.dtsi:257 */
			#address-cells = < 0x1 >;          /* in zephyr\dts\arm\st\g0\stm32g0.dtsi:259 */
			#size-cells = < 0x0 >;             /* in zephyr\dts\arm\st\g0\stm32g0.dtsi:260 */
			reg = < 0x40007c00 0x400 >;        /* in zephyr\dts\arm\st\g0\stm32g0.dtsi:261 */
			interrupts = < 0x11 0x1 >;         /* in zephyr\dts\arm\st\g0\stm32g0.dtsi:262 */
			interrupt-names = "wakeup";        /* in zephyr\dts\arm\st\g0\stm32g0.dtsi:263 */
			clocks = < &rcc 0x3c 0x80000000 >,
			         < &rcc 0x3 0x8d20054 >;   /* in zephyr\boards\st\nucleo_g071rb\nucleo_g071rb.dts:183 */
			status = "okay";                   /* in zephyr\boards\st\nucleo_g071rb\nucleo_g071rb.dts:185 */
		};

		/* node '/soc/timers@40012c00' defined in zephyr\dts\arm\st\g0\stm32g0.dtsi:267 */
		timers1: timers@40012c00 {
			compatible = "st,stm32-timers";     /* in zephyr\dts\arm\st\g0\stm32g0.dtsi:268 */
			reg = < 0x40012c00 0x400 >;         /* in zephyr\dts\arm\st\g0\stm32g0.dtsi:269 */
			resets = < &rctl 0x60b >;           /* in zephyr\dts\arm\st\g0\stm32g0.dtsi:272 */
			interrupts = < 0xd 0x0 >,
			             < 0xe 0x0 >;           /* in zephyr\dts\arm\st\g0\stm32g0.dtsi:273 */
			interrupt-names = "brk_up_trg_com",
			                  "cc";             /* in zephyr\dts\arm\st\g0\stm32g0.dtsi:274 */
			st,prescaler = < 0x0 >;             /* in zephyr\dts\arm\st\g0\stm32g0.dtsi:275 */
			status = "disabled";                /* in zephyr\dts\arm\st\g0\stm32g0.dtsi:276 */
			clocks = < &rcc 0x40 0x800 >,
			         < &rcc 0x9 0x560054 >;     /* in zephyr\dts\arm\st\g0\stm32g031.dtsi:24 */

			/* node '/soc/timers@40012c00/pwm' defined in zephyr\dts\arm\st\g0\stm32g0.dtsi:278 */
			pwm {
				compatible = "st,stm32-pwm"; /* in zephyr\dts\arm\st\g0\stm32g0.dtsi:279 */
				status = "disabled";         /* in zephyr\dts\arm\st\g0\stm32g0.dtsi:280 */
				#pwm-cells = < 0x3 >;        /* in zephyr\dts\arm\st\g0\stm32g0.dtsi:281 */
			};

			/* node '/soc/timers@40012c00/counter' defined in zephyr\dts\arm\st\g0\stm32g0.dtsi:284 */
			counter {
				compatible = "st,stm32-counter"; /* in zephyr\dts\arm\st\g0\stm32g0.dtsi:285 */
				status = "disabled";             /* in zephyr\dts\arm\st\g0\stm32g0.dtsi:286 */
			};
		};

		/* node '/soc/timers@40000400' defined in zephyr\dts\arm\st\g0\stm32g0.dtsi:290 */
		timers3: timers@40000400 {
			compatible = "st,stm32-timers"; /* in zephyr\dts\arm\st\g0\stm32g0.dtsi:291 */
			reg = < 0x40000400 0x400 >;     /* in zephyr\dts\arm\st\g0\stm32g0.dtsi:292 */
			clocks = < &rcc 0x3c 0x2 >,
			         < &rcc 0x9 0xff >;     /* in zephyr\dts\arm\st\g0\stm32g0.dtsi:293 */
			resets = < &rctl 0x581 >;       /* in zephyr\dts\arm\st\g0\stm32g0.dtsi:295 */
			interrupts = < 0x10 0x0 >;      /* in zephyr\dts\arm\st\g0\stm32g0.dtsi:296 */
			interrupt-names = "global";     /* in zephyr\dts\arm\st\g0\stm32g0.dtsi:297 */
			st,prescaler = < 0x2710 >;      /* in zephyr\boards\st\nucleo_g071rb\nucleo_g071rb.dts:109 */
			status = "okay";                /* in zephyr\boards\st\nucleo_g071rb\nucleo_g071rb.dts:110 */

			/* node '/soc/timers@40000400/pwm' defined in zephyr\dts\arm\st\g0\stm32g0.dtsi:301 */
			pwm3: pwm {
				compatible = "st,stm32-pwm";   /* in zephyr\dts\arm\st\g0\stm32g0.dtsi:302 */
				#pwm-cells = < 0x3 >;          /* in zephyr\dts\arm\st\g0\stm32g0.dtsi:304 */
				status = "okay";               /* in zephyr\boards\st\nucleo_g071rb\nucleo_g071rb.dts:113 */
				pinctrl-0 = < &tim3_ch1_pa6 >; /* in zephyr\boards\st\nucleo_g071rb\nucleo_g071rb.dts:114 */
				pinctrl-names = "default";     /* in zephyr\boards\st\nucleo_g071rb\nucleo_g071rb.dts:115 */
			};

			/* node '/soc/timers@40000400/counter' defined in zephyr\dts\arm\st\g0\stm32g0.dtsi:307 */
			counter {
				compatible = "st,stm32-counter"; /* in zephyr\dts\arm\st\g0\stm32g0.dtsi:308 */
				status = "disabled";             /* in zephyr\dts\arm\st\g0\stm32g0.dtsi:309 */
			};
		};

		/* node '/soc/timers@40002000' defined in zephyr\dts\arm\st\g0\stm32g0.dtsi:313 */
		timers14: timers@40002000 {
			compatible = "st,stm32-timers"; /* in zephyr\dts\arm\st\g0\stm32g0.dtsi:314 */
			reg = < 0x40002000 0x400 >;     /* in zephyr\dts\arm\st\g0\stm32g0.dtsi:315 */
			clocks = < &rcc 0x40 0x8000 >,
			         < &rcc 0x9 0xff >;     /* in zephyr\dts\arm\st\g0\stm32g0.dtsi:316 */
			resets = < &rctl 0x60f >;       /* in zephyr\dts\arm\st\g0\stm32g0.dtsi:318 */
			interrupts = < 0x13 0x0 >;      /* in zephyr\dts\arm\st\g0\stm32g0.dtsi:319 */
			interrupt-names = "global";     /* in zephyr\dts\arm\st\g0\stm32g0.dtsi:320 */
			st,prescaler = < 0x0 >;         /* in zephyr\dts\arm\st\g0\stm32g0.dtsi:321 */
			status = "disabled";            /* in zephyr\dts\arm\st\g0\stm32g0.dtsi:322 */

			/* node '/soc/timers@40002000/pwm' defined in zephyr\dts\arm\st\g0\stm32g0.dtsi:324 */
			pwm {
				compatible = "st,stm32-pwm"; /* in zephyr\dts\arm\st\g0\stm32g0.dtsi:325 */
				status = "disabled";         /* in zephyr\dts\arm\st\g0\stm32g0.dtsi:326 */
				#pwm-cells = < 0x3 >;        /* in zephyr\dts\arm\st\g0\stm32g0.dtsi:327 */
			};

			/* node '/soc/timers@40002000/counter' defined in zephyr\dts\arm\st\g0\stm32g0.dtsi:330 */
			counter {
				compatible = "st,stm32-counter"; /* in zephyr\dts\arm\st\g0\stm32g0.dtsi:331 */
				status = "disabled";             /* in zephyr\dts\arm\st\g0\stm32g0.dtsi:332 */
			};
		};

		/* node '/soc/timers@40014400' defined in zephyr\dts\arm\st\g0\stm32g0.dtsi:336 */
		timers16: timers@40014400 {
			compatible = "st,stm32-timers"; /* in zephyr\dts\arm\st\g0\stm32g0.dtsi:337 */
			reg = < 0x40014400 0x400 >;     /* in zephyr\dts\arm\st\g0\stm32g0.dtsi:338 */
			clocks = < &rcc 0x40 0x20000 >,
			         < &rcc 0x9 0xff >;     /* in zephyr\dts\arm\st\g0\stm32g0.dtsi:339 */
			resets = < &rctl 0x611 >;       /* in zephyr\dts\arm\st\g0\stm32g0.dtsi:341 */
			interrupts = < 0x15 0x0 >;      /* in zephyr\dts\arm\st\g0\stm32g0.dtsi:342 */
			interrupt-names = "global";     /* in zephyr\dts\arm\st\g0\stm32g0.dtsi:343 */
			st,prescaler = < 0x0 >;         /* in zephyr\dts\arm\st\g0\stm32g0.dtsi:344 */
			status = "disabled";            /* in zephyr\dts\arm\st\g0\stm32g0.dtsi:345 */

			/* node '/soc/timers@40014400/pwm' defined in zephyr\dts\arm\st\g0\stm32g0.dtsi:347 */
			pwm {
				compatible = "st,stm32-pwm"; /* in zephyr\dts\arm\st\g0\stm32g0.dtsi:348 */
				status = "disabled";         /* in zephyr\dts\arm\st\g0\stm32g0.dtsi:349 */
				#pwm-cells = < 0x3 >;        /* in zephyr\dts\arm\st\g0\stm32g0.dtsi:350 */
			};

			/* node '/soc/timers@40014400/counter' defined in zephyr\dts\arm\st\g0\stm32g0.dtsi:353 */
			counter {
				compatible = "st,stm32-counter"; /* in zephyr\dts\arm\st\g0\stm32g0.dtsi:354 */
				status = "disabled";             /* in zephyr\dts\arm\st\g0\stm32g0.dtsi:355 */
			};
		};

		/* node '/soc/timers@40014800' defined in zephyr\dts\arm\st\g0\stm32g0.dtsi:359 */
		timers17: timers@40014800 {
			compatible = "st,stm32-timers"; /* in zephyr\dts\arm\st\g0\stm32g0.dtsi:360 */
			reg = < 0x40014800 0x400 >;     /* in zephyr\dts\arm\st\g0\stm32g0.dtsi:361 */
			clocks = < &rcc 0x40 0x40000 >,
			         < &rcc 0x9 0xff >;     /* in zephyr\dts\arm\st\g0\stm32g0.dtsi:362 */
			resets = < &rctl 0x612 >;       /* in zephyr\dts\arm\st\g0\stm32g0.dtsi:364 */
			interrupts = < 0x16 0x0 >;      /* in zephyr\dts\arm\st\g0\stm32g0.dtsi:365 */
			interrupt-names = "global";     /* in zephyr\dts\arm\st\g0\stm32g0.dtsi:366 */
			st,prescaler = < 0x0 >;         /* in zephyr\dts\arm\st\g0\stm32g0.dtsi:367 */
			status = "disabled";            /* in zephyr\dts\arm\st\g0\stm32g0.dtsi:368 */

			/* node '/soc/timers@40014800/pwm' defined in zephyr\dts\arm\st\g0\stm32g0.dtsi:370 */
			pwm {
				compatible = "st,stm32-pwm"; /* in zephyr\dts\arm\st\g0\stm32g0.dtsi:371 */
				status = "disabled";         /* in zephyr\dts\arm\st\g0\stm32g0.dtsi:372 */
				#pwm-cells = < 0x3 >;        /* in zephyr\dts\arm\st\g0\stm32g0.dtsi:373 */
			};

			/* node '/soc/timers@40014800/counter' defined in zephyr\dts\arm\st\g0\stm32g0.dtsi:376 */
			counter {
				compatible = "st,stm32-counter"; /* in zephyr\dts\arm\st\g0\stm32g0.dtsi:377 */
				status = "disabled";             /* in zephyr\dts\arm\st\g0\stm32g0.dtsi:378 */
			};
		};

		/* node '/soc/i2c@40005400' defined in zephyr\dts\arm\st\g0\stm32g0.dtsi:382 */
		i2c1: arduino_i2c: i2c@40005400 {
			compatible = "st,stm32-i2c-v2";              /* in zephyr\dts\arm\st\g0\stm32g0.dtsi:383 */
			#address-cells = < 0x1 >;                    /* in zephyr\dts\arm\st\g0\stm32g0.dtsi:385 */
			#size-cells = < 0x0 >;                       /* in zephyr\dts\arm\st\g0\stm32g0.dtsi:386 */
			reg = < 0x40005400 0x400 >;                  /* in zephyr\dts\arm\st\g0\stm32g0.dtsi:387 */
			clocks = < &rcc 0x3c 0x200000 >;             /* in zephyr\dts\arm\st\g0\stm32g0.dtsi:388 */
			interrupts = < 0x17 0x0 >;                   /* in zephyr\dts\arm\st\g0\stm32g0.dtsi:389 */
			interrupt-names = "combined";                /* in zephyr\dts\arm\st\g0\stm32g0.dtsi:390 */
			pinctrl-0 = < &i2c1_scl_pb8 &i2c1_sda_pb9 >; /* in zephyr\boards\st\nucleo_g071rb\nucleo_g071rb.dts:120 */
			pinctrl-names = "default";                   /* in zephyr\boards\st\nucleo_g071rb\nucleo_g071rb.dts:121 */
			status = "okay";                             /* in zephyr\boards\st\nucleo_g071rb\nucleo_g071rb.dts:122 */
			clock-frequency = < 0x61a80 >;               /* in zephyr\boards\st\nucleo_g071rb\nucleo_g071rb.dts:123 */
			phandle = < 0x20 >;                          /* in zephyr\dts\arm\st\g0\stm32g0.dtsi:544 */
		};

		/* node '/soc/i2c@40005800' defined in zephyr\dts\arm\st\g0\stm32g0.dtsi:394 */
		i2c2: i2c@40005800 {
			compatible = "st,stm32-i2c-v2";                /* in zephyr\dts\arm\st\g0\stm32g0.dtsi:395 */
			#address-cells = < 0x1 >;                      /* in zephyr\dts\arm\st\g0\stm32g0.dtsi:397 */
			#size-cells = < 0x0 >;                         /* in zephyr\dts\arm\st\g0\stm32g0.dtsi:398 */
			reg = < 0x40005800 0x400 >;                    /* in zephyr\dts\arm\st\g0\stm32g0.dtsi:399 */
			clocks = < &rcc 0x3c 0x400000 >;               /* in zephyr\dts\arm\st\g0\stm32g0.dtsi:400 */
			interrupts = < 0x18 0x0 >;                     /* in zephyr\dts\arm\st\g0\stm32g0.dtsi:401 */
			interrupt-names = "combined";                  /* in zephyr\dts\arm\st\g0\stm32g0.dtsi:402 */
			pinctrl-0 = < &i2c2_scl_pa11 &i2c2_sda_pa12 >; /* in zephyr\boards\st\nucleo_g071rb\nucleo_g071rb.dts:127 */
			pinctrl-names = "default";                     /* in zephyr\boards\st\nucleo_g071rb\nucleo_g071rb.dts:128 */
			status = "okay";                               /* in zephyr\boards\st\nucleo_g071rb\nucleo_g071rb.dts:129 */
			clock-frequency = < 0x61a80 >;                 /* in zephyr\boards\st\nucleo_g071rb\nucleo_g071rb.dts:130 */
			phandle = < 0x21 >;                            /* in zephyr\dts\arm\st\g0\stm32g0.dtsi:552 */
		};

		/* node '/soc/spi@40013000' defined in zephyr\dts\arm\st\g0\stm32g0.dtsi:406 */
		spi1: arduino_spi: spi@40013000 {
			compatible = "st,stm32-spi-fifo",
			             "st,stm32-spi";                                               /* in zephyr\dts\arm\st\g0\stm32g0.dtsi:407 */
			#address-cells = < 0x1 >;                                                  /* in zephyr\dts\arm\st\g0\stm32g0.dtsi:408 */
			#size-cells = < 0x0 >;                                                     /* in zephyr\dts\arm\st\g0\stm32g0.dtsi:409 */
			reg = < 0x40013000 0x400 >;                                                /* in zephyr\dts\arm\st\g0\stm32g0.dtsi:410 */
			clocks = < &rcc 0x40 0x1000 >;                                             /* in zephyr\dts\arm\st\g0\stm32g0.dtsi:411 */
			interrupts = < 0x19 0x0 >;                                                 /* in zephyr\dts\arm\st\g0\stm32g0.dtsi:412 */
			pinctrl-0 = < &spi1_nss_pb0 &spi1_sck_pa5 &spi1_miso_pa6 &spi1_mosi_pa7 >; /* in zephyr\boards\st\nucleo_g071rb\nucleo_g071rb.dts:134 */
			pinctrl-names = "default";                                                 /* in zephyr\boards\st\nucleo_g071rb\nucleo_g071rb.dts:136 */
			status = "okay";                                                           /* in zephyr\boards\st\nucleo_g071rb\nucleo_g071rb.dts:137 */
		};

		/* node '/soc/spi@40003800' defined in zephyr\dts\arm\st\g0\stm32g0.dtsi:416 */
		spi2: spi@40003800 {
			compatible = "st,stm32-spi-fifo",
			             "st,stm32-spi";                                                   /* in zephyr\dts\arm\st\g0\stm32g0.dtsi:417 */
			#address-cells = < 0x1 >;                                                      /* in zephyr\dts\arm\st\g0\stm32g0.dtsi:418 */
			#size-cells = < 0x0 >;                                                         /* in zephyr\dts\arm\st\g0\stm32g0.dtsi:419 */
			reg = < 0x40003800 0x400 >;                                                    /* in zephyr\dts\arm\st\g0\stm32g0.dtsi:420 */
			clocks = < &rcc 0x3c 0x4000 >;                                                 /* in zephyr\dts\arm\st\g0\stm32g0.dtsi:421 */
			interrupts = < 0x1a 0x0 >;                                                     /* in zephyr\dts\arm\st\g0\stm32g0.dtsi:422 */
			pinctrl-0 = < &spi2_nss_pb12 &spi2_sck_pb13 &spi2_miso_pb14 &spi2_mosi_pb15 >; /* in zephyr\boards\st\nucleo_g071rb\nucleo_g071rb.dts:141 */
			pinctrl-names = "default";                                                     /* in zephyr\boards\st\nucleo_g071rb\nucleo_g071rb.dts:143 */
			status = "okay";                                                               /* in zephyr\boards\st\nucleo_g071rb\nucleo_g071rb.dts:144 */
		};

		/* node '/soc/adc@40012400' defined in zephyr\dts\arm\st\g0\stm32g0.dtsi:426 */
		adc1: adc@40012400 {
			compatible = "st,stm32-adc";                              /* in zephyr\dts\arm\st\g0\stm32g0.dtsi:427 */
			reg = < 0x40012400 0x400 >;                               /* in zephyr\dts\arm\st\g0\stm32g0.dtsi:428 */
			interrupts = < 0xc 0x0 >;                                 /* in zephyr\dts\arm\st\g0\stm32g0.dtsi:430 */
			#io-channel-cells = < 0x1 >;                              /* in zephyr\dts\arm\st\g0\stm32g0.dtsi:432 */
			resolutions = < 0x60630c 0x51630c 0x42630c 0x33630c >;    /* in zephyr\dts\arm\st\g0\stm32g0.dtsi:433 */
			sampling-times = < 0x3 0x5 0x8 0xd 0x14 0x28 0x50 0xa1 >; /* in zephyr\dts\arm\st\g0\stm32g0.dtsi:443 */
			num-sampling-time-common-channels = < 0x2 >;              /* in zephyr\dts\arm\st\g0\stm32g0.dtsi:444 */
			st,adc-sequencer = "NOT_FULLY_CONFIGURABLE";              /* in zephyr\dts\arm\st\g0\stm32g0.dtsi:445 */
			st,adc-oversampler = "OVERSAMPLER_MINIMAL";               /* in zephyr\dts\arm\st\g0\stm32g0.dtsi:446 */
			clocks = < &rcc 0x40 0x100000 >,
			         < &rcc 0x1 0xde0054 >;                           /* in zephyr\boards\st\nucleo_g071rb\nucleo_g071rb.dts:148 */
			pinctrl-0 = < &adc1_in0_pa0 &adc1_in1_pa1 >;              /* in zephyr\boards\st\nucleo_g071rb\nucleo_g071rb.dts:150 */
			pinctrl-names = "default";                                /* in zephyr\boards\st\nucleo_g071rb\nucleo_g071rb.dts:151 */
			st,adc-clock-source = "ASYNC";                            /* in zephyr\boards\st\nucleo_g071rb\nucleo_g071rb.dts:152 */
			st,adc-prescaler = < 0x4 >;                               /* in zephyr\boards\st\nucleo_g071rb\nucleo_g071rb.dts:153 */
			status = "okay";                                          /* in zephyr\boards\st\nucleo_g071rb\nucleo_g071rb.dts:154 */
			vref-mv = < 0xce4 >;                                      /* in zephyr\boards\st\nucleo_g071rb\nucleo_g071rb.dts:155 */
			phandle = < 0x1f >;                                       /* in zephyr\dts\arm\st\g0\stm32g0.dtsi:521 */
		};

		/* node '/soc/dma@40020000' defined in zephyr\dts\arm\st\g0\stm32g0.dtsi:449 */
		dma1: dma@40020000 {
			compatible = "st,stm32-dma-v2";                                           /* in zephyr\dts\arm\st\g0\stm32g0.dtsi:450 */
			#dma-cells = < 0x3 >;                                                     /* in zephyr\dts\arm\st\g0\stm32g0.dtsi:451 */
			reg = < 0x40020000 0x400 >;                                               /* in zephyr\dts\arm\st\g0\stm32g0.dtsi:452 */
			clocks = < &rcc 0x38 0x1 >;                                               /* in zephyr\dts\arm\st\g0\stm32g0.dtsi:454 */
			dma-offset = < 0x0 >;                                                     /* in zephyr\dts\arm\st\g0\stm32g0.dtsi:456 */
			status = "disabled";                                                      /* in zephyr\dts\arm\st\g0\stm32g0.dtsi:457 */
			interrupts = < 0x9 0x0 0xa 0x0 0xa 0x0 0xb 0x0 0xb 0x0 0xb 0x0 0xb 0x0 >; /* in zephyr\dts\arm\st\g0\stm32g051.dtsi:78 */
			dma-requests = < 0x7 >;                                                   /* in zephyr\dts\arm\st\g0\stm32g051.dtsi:79 */
		};

		/* node '/soc/dmamux@40020800' defined in zephyr\dts\arm\st\g0\stm32g0.dtsi:461 */
		dmamux1: dmamux@40020800 {
			compatible = "st,stm32-dmamux"; /* in zephyr\dts\arm\st\g0\stm32g0.dtsi:462 */
			#dma-cells = < 0x3 >;           /* in zephyr\dts\arm\st\g0\stm32g0.dtsi:463 */
			reg = < 0x40020800 0x800 >;     /* in zephyr\dts\arm\st\g0\stm32g0.dtsi:464 */
			interrupts = < 0xb 0x0 >;       /* in zephyr\dts\arm\st\g0\stm32g0.dtsi:465 */
			dma-generators = < 0x4 >;       /* in zephyr\dts\arm\st\g0\stm32g0.dtsi:467 */
			status = "disabled";            /* in zephyr\dts\arm\st\g0\stm32g0.dtsi:469 */
			dma-channels = < 0x7 >;         /* in zephyr\dts\arm\st\g0\stm32g051.dtsi:83 */
			dma-requests = < 0x39 >;        /* in zephyr\dts\arm\st\g0\stm32g071.dtsi:34 */
		};

		/* node '/soc/power@40007000' defined in zephyr\dts\arm\st\g0\stm32g0.dtsi:472 */
		pwr: power@40007000 {
			compatible = "st,stm32-pwr"; /* in zephyr\dts\arm\st\g0\stm32g0.dtsi:473 */
			reg = < 0x40007000 0x400 >;  /* in zephyr\dts\arm\st\g0\stm32g0.dtsi:474 */
			status = "disabled";         /* in zephyr\dts\arm\st\g0\stm32g0.dtsi:475 */
			wkup-pins-nb = < 0x6 >;      /* in zephyr\dts\arm\st\g0\stm32g0.dtsi:477 */
			wkup-pins-pol;               /* in zephyr\dts\arm\st\g0\stm32g0.dtsi:478 */
			wkup-pins-pupd;              /* in zephyr\dts\arm\st\g0\stm32g0.dtsi:479 */
			#address-cells = < 0x1 >;    /* in zephyr\dts\arm\st\g0\stm32g0.dtsi:481 */
			#size-cells = < 0x0 >;       /* in zephyr\dts\arm\st\g0\stm32g0.dtsi:482 */

			/* node '/soc/power@40007000/wkup-pin@1' defined in zephyr\dts\arm\st\g0\stm32g0.dtsi:484 */
			wkup-pin@1 {
				reg = < 0x1 >;                   /* in zephyr\dts\arm\st\g0\stm32g0.dtsi:485 */
				wkup-gpios = < &gpioa 0x0 0x1 >; /* in zephyr\dts\arm\st\g0\stm32g0.dtsi:486 */
			};

			/* node '/soc/power@40007000/wkup-pin@2' defined in zephyr\dts\arm\st\g0\stm32g0.dtsi:489 */
			wkup-pin@2 {
				reg = < 0x2 >;                   /* in zephyr\dts\arm\st\g0\stm32g0.dtsi:490 */
				wkup-gpios = < &gpioa 0x4 0x1 >,
				             < &gpioc 0xd 0x1 >; /* in zephyr\dts\arm\st\g0\stm32g0.dtsi:491 */
			};

			/* node '/soc/power@40007000/wkup-pin@4' defined in zephyr\dts\arm\st\g0\stm32g0.dtsi:497 */
			wkup-pin@4 {
				reg = < 0x4 >;                   /* in zephyr\dts\arm\st\g0\stm32g0.dtsi:498 */
				wkup-gpios = < &gpioa 0x2 0x1 >; /* in zephyr\dts\arm\st\g0\stm32g0.dtsi:499 */
			};

			/* node '/soc/power@40007000/wkup-pin@5' defined in zephyr\dts\arm\st\g0\stm32g0.dtsi:502 */
			wkup-pin@5 {
				reg = < 0x5 >;                   /* in zephyr\dts\arm\st\g0\stm32g0.dtsi:503 */
				wkup-gpios = < &gpioc 0x5 0x1 >; /* in zephyr\dts\arm\st\g0\stm32g0.dtsi:504 */
			};

			/* node '/soc/power@40007000/wkup-pin@6' defined in zephyr\dts\arm\st\g0\stm32g0.dtsi:507 */
			wkup-pin@6 {
				reg = < 0x6 >;                   /* in zephyr\dts\arm\st\g0\stm32g0.dtsi:508 */
				wkup-gpios = < &gpiob 0x5 0x1 >; /* in zephyr\dts\arm\st\g0\stm32g0.dtsi:509 */
			};
		};

		/* node '/soc/serial@40008000' defined in zephyr\dts\arm\st\g0\stm32g031.dtsi:14 */
		lpuart1: serial@40008000 {
			compatible = "st,stm32-lpuart",
			             "st,stm32-uart";    /* in zephyr\dts\arm\st\g0\stm32g031.dtsi:15 */
			reg = < 0x40008000 0x400 >;      /* in zephyr\dts\arm\st\g0\stm32g031.dtsi:16 */
			clocks = < &rcc 0x3c 0x100000 >; /* in zephyr\dts\arm\st\g0\stm32g031.dtsi:17 */
			resets = < &rctl 0x594 >;        /* in zephyr\dts\arm\st\g0\stm32g031.dtsi:18 */
			interrupts = < 0x1d 0x0 >;       /* in zephyr\dts\arm\st\g0\stm32g031.dtsi:19 */
			status = "disabled";             /* in zephyr\dts\arm\st\g0\stm32g031.dtsi:20 */
		};

		/* node '/soc/timers@40000000' defined in zephyr\dts\arm\st\g0\stm32g031.dtsi:28 */
		timers2: timers@40000000 {
			compatible = "st,stm32-timers"; /* in zephyr\dts\arm\st\g0\stm32g031.dtsi:29 */
			reg = < 0x40000000 0x400 >;     /* in zephyr\dts\arm\st\g0\stm32g031.dtsi:30 */
			clocks = < &rcc 0x3c 0x1 >,
			         < &rcc 0x9 0xff >;     /* in zephyr\dts\arm\st\g0\stm32g031.dtsi:31 */
			resets = < &rctl 0x580 >;       /* in zephyr\dts\arm\st\g0\stm32g031.dtsi:33 */
			interrupts = < 0xf 0x0 >;       /* in zephyr\dts\arm\st\g0\stm32g031.dtsi:34 */
			interrupt-names = "global";     /* in zephyr\dts\arm\st\g0\stm32g031.dtsi:35 */
			st,prescaler = < 0x0 >;         /* in zephyr\dts\arm\st\g0\stm32g031.dtsi:36 */
			status = "disabled";            /* in zephyr\dts\arm\st\g0\stm32g031.dtsi:37 */

			/* node '/soc/timers@40000000/pwm' defined in zephyr\dts\arm\st\g0\stm32g031.dtsi:39 */
			pwm {
				compatible = "st,stm32-pwm"; /* in zephyr\dts\arm\st\g0\stm32g031.dtsi:40 */
				status = "disabled";         /* in zephyr\dts\arm\st\g0\stm32g031.dtsi:41 */
				#pwm-cells = < 0x3 >;        /* in zephyr\dts\arm\st\g0\stm32g031.dtsi:42 */
			};
		};

		/* node '/soc/timers@40001000' defined in zephyr\dts\arm\st\g0\stm32g051.dtsi:13 */
		timers6: timers@40001000 {
			compatible = "st,stm32-timers"; /* in zephyr\dts\arm\st\g0\stm32g051.dtsi:14 */
			reg = < 0x40001000 0x400 >;     /* in zephyr\dts\arm\st\g0\stm32g051.dtsi:15 */
			clocks = < &rcc 0x3c 0x10 >,
			         < &rcc 0x9 0xff >;     /* in zephyr\dts\arm\st\g0\stm32g051.dtsi:16 */
			resets = < &rctl 0x584 >;       /* in zephyr\dts\arm\st\g0\stm32g051.dtsi:18 */
			interrupts = < 0x11 0x0 >;      /* in zephyr\dts\arm\st\g0\stm32g051.dtsi:19 */
			interrupt-names = "global";     /* in zephyr\dts\arm\st\g0\stm32g051.dtsi:20 */
			status = "disabled";            /* in zephyr\dts\arm\st\g0\stm32g051.dtsi:21 */

			/* node '/soc/timers@40001000/counter' defined in zephyr\dts\arm\st\g0\stm32g051.dtsi:23 */
			counter {
				compatible = "st,stm32-counter"; /* in zephyr\dts\arm\st\g0\stm32g051.dtsi:24 */
				status = "disabled";             /* in zephyr\dts\arm\st\g0\stm32g051.dtsi:25 */
			};
		};

		/* node '/soc/timers@40001400' defined in zephyr\dts\arm\st\g0\stm32g051.dtsi:29 */
		timers7: timers@40001400 {
			compatible = "st,stm32-timers"; /* in zephyr\dts\arm\st\g0\stm32g051.dtsi:30 */
			reg = < 0x40001400 0x400 >;     /* in zephyr\dts\arm\st\g0\stm32g051.dtsi:31 */
			clocks = < &rcc 0x3c 0x20 >,
			         < &rcc 0x9 0xff >;     /* in zephyr\dts\arm\st\g0\stm32g051.dtsi:32 */
			resets = < &rctl 0x585 >;       /* in zephyr\dts\arm\st\g0\stm32g051.dtsi:34 */
			interrupts = < 0x12 0x0 >;      /* in zephyr\dts\arm\st\g0\stm32g051.dtsi:35 */
			interrupt-names = "global";     /* in zephyr\dts\arm\st\g0\stm32g051.dtsi:36 */
			st,prescaler = < 0x0 >;         /* in zephyr\dts\arm\st\g0\stm32g051.dtsi:37 */
			status = "disabled";            /* in zephyr\dts\arm\st\g0\stm32g051.dtsi:38 */

			/* node '/soc/timers@40001400/counter' defined in zephyr\dts\arm\st\g0\stm32g051.dtsi:40 */
			counter {
				compatible = "st,stm32-counter"; /* in zephyr\dts\arm\st\g0\stm32g051.dtsi:41 */
				status = "disabled";             /* in zephyr\dts\arm\st\g0\stm32g051.dtsi:42 */
			};
		};

		/* node '/soc/timers@40014000' defined in zephyr\dts\arm\st\g0\stm32g051.dtsi:46 */
		timers15: timers@40014000 {
			compatible = "st,stm32-timers"; /* in zephyr\dts\arm\st\g0\stm32g051.dtsi:47 */
			reg = < 0x40014000 0x400 >;     /* in zephyr\dts\arm\st\g0\stm32g051.dtsi:48 */
			clocks = < &rcc 0x40 0x10000 >,
			         < &rcc 0x9 0x580054 >; /* in zephyr\dts\arm\st\g0\stm32g051.dtsi:49 */
			resets = < &rctl 0x610 >;       /* in zephyr\dts\arm\st\g0\stm32g051.dtsi:51 */
			interrupts = < 0x14 0x0 >;      /* in zephyr\dts\arm\st\g0\stm32g051.dtsi:52 */
			interrupt-names = "global";     /* in zephyr\dts\arm\st\g0\stm32g051.dtsi:53 */
			st,prescaler = < 0x0 >;         /* in zephyr\dts\arm\st\g0\stm32g051.dtsi:54 */
			status = "disabled";            /* in zephyr\dts\arm\st\g0\stm32g051.dtsi:55 */

			/* node '/soc/timers@40014000/pwm' defined in zephyr\dts\arm\st\g0\stm32g051.dtsi:57 */
			pwm {
				compatible = "st,stm32-pwm"; /* in zephyr\dts\arm\st\g0\stm32g051.dtsi:58 */
				status = "disabled";         /* in zephyr\dts\arm\st\g0\stm32g051.dtsi:59 */
				#pwm-cells = < 0x3 >;        /* in zephyr\dts\arm\st\g0\stm32g051.dtsi:60 */
			};

			/* node '/soc/timers@40014000/counter' defined in zephyr\dts\arm\st\g0\stm32g051.dtsi:63 */
			counter {
				compatible = "st,stm32-counter"; /* in zephyr\dts\arm\st\g0\stm32g051.dtsi:64 */
				status = "disabled";             /* in zephyr\dts\arm\st\g0\stm32g051.dtsi:65 */
			};
		};

		/* node '/soc/dac@40007400' defined in zephyr\dts\arm\st\g0\stm32g051.dtsi:69 */
		dac1: dac@40007400 {
			compatible = "st,stm32-dac";       /* in zephyr\dts\arm\st\g0\stm32g051.dtsi:70 */
			reg = < 0x40007400 0x400 >;        /* in zephyr\dts\arm\st\g0\stm32g051.dtsi:71 */
			clocks = < &rcc 0x3c 0x20000000 >; /* in zephyr\dts\arm\st\g0\stm32g051.dtsi:72 */
			#io-channel-cells = < 0x1 >;       /* in zephyr\dts\arm\st\g0\stm32g051.dtsi:74 */
			status = "okay";                   /* in zephyr\boards\st\nucleo_g071rb\nucleo_g071rb.dts:159 */
			pinctrl-0 = < &dac1_out1_pa4 >;    /* in zephyr\boards\st\nucleo_g071rb\nucleo_g071rb.dts:160 */
			pinctrl-names = "default";         /* in zephyr\boards\st\nucleo_g071rb\nucleo_g071rb.dts:161 */
		};

		/* node '/soc/serial@40004800' defined in zephyr\dts\arm\st\g0\stm32g071.dtsi:15 */
		usart3: serial@40004800 {
			compatible = "st,stm32-usart",
			             "st,stm32-uart";   /* in zephyr\dts\arm\st\g0\stm32g071.dtsi:16 */
			reg = < 0x40004800 0x400 >;     /* in zephyr\dts\arm\st\g0\stm32g071.dtsi:17 */
			clocks = < &rcc 0x3c 0x40000 >; /* in zephyr\dts\arm\st\g0\stm32g071.dtsi:18 */
			resets = < &rctl 0x592 >;       /* in zephyr\dts\arm\st\g0\stm32g071.dtsi:19 */
			interrupts = < 0x1d 0x0 >;      /* in zephyr\dts\arm\st\g0\stm32g071.dtsi:20 */
			status = "disabled";            /* in zephyr\dts\arm\st\g0\stm32g071.dtsi:21 */
		};

		/* node '/soc/serial@40004c00' defined in zephyr\dts\arm\st\g0\stm32g071.dtsi:24 */
		usart4: serial@40004c00 {
			compatible = "st,stm32-usart",
			             "st,stm32-uart";   /* in zephyr\dts\arm\st\g0\stm32g071.dtsi:25 */
			reg = < 0x40004c00 0x400 >;     /* in zephyr\dts\arm\st\g0\stm32g071.dtsi:26 */
			clocks = < &rcc 0x3c 0x80000 >; /* in zephyr\dts\arm\st\g0\stm32g071.dtsi:27 */
			resets = < &rctl 0x593 >;       /* in zephyr\dts\arm\st\g0\stm32g071.dtsi:28 */
			interrupts = < 0x1d 0x0 >;      /* in zephyr\dts\arm\st\g0\stm32g071.dtsi:29 */
			status = "disabled";            /* in zephyr\dts\arm\st\g0\stm32g071.dtsi:30 */
		};

		/* node '/soc/ucpd@4000a000' defined in zephyr\dts\arm\st\g0\stm32g071.dtsi:37 */
		ucpd1: ucpd@4000a000 {
			compatible = "st,stm32-ucpd";     /* in zephyr\dts\arm\st\g0\stm32g071.dtsi:38 */
			reg = < 0x4000a000 0x400 >;       /* in zephyr\dts\arm\st\g0\stm32g071.dtsi:39 */
			clocks = < &rcc 0x3c 0x2000000 >; /* in zephyr\dts\arm\st\g0\stm32g071.dtsi:40 */
			interrupts = < 0x8 0x0 >;         /* in zephyr\dts\arm\st\g0\stm32g071.dtsi:41 */
			status = "disabled";              /* in zephyr\dts\arm\st\g0\stm32g071.dtsi:42 */
		};

		/* node '/soc/ucpd@4000a400' defined in zephyr\dts\arm\st\g0\stm32g071.dtsi:45 */
		ucpd2: ucpd@4000a400 {
			compatible = "st,stm32-ucpd";     /* in zephyr\dts\arm\st\g0\stm32g071.dtsi:46 */
			reg = < 0x4000a400 0x400 >;       /* in zephyr\dts\arm\st\g0\stm32g071.dtsi:47 */
			clocks = < &rcc 0x3c 0x4000000 >; /* in zephyr\dts\arm\st\g0\stm32g071.dtsi:48 */
			interrupts = < 0x8 0x0 >;         /* in zephyr\dts\arm\st\g0\stm32g071.dtsi:49 */
			status = "disabled";              /* in zephyr\dts\arm\st\g0\stm32g071.dtsi:50 */
		};
	};

	/* node '/cpus' defined in zephyr\dts\arm\st\g0\stm32g0.dtsi:29 */
	cpus {
		#address-cells = < 0x1 >; /* in zephyr\dts\arm\st\g0\stm32g0.dtsi:30 */
		#size-cells = < 0x0 >;    /* in zephyr\dts\arm\st\g0\stm32g0.dtsi:31 */

		/* node '/cpus/cpu@0' defined in zephyr\dts\arm\st\g0\stm32g0.dtsi:33 */
		cpu0: cpu@0 {
			device_type = "cpu";                  /* in zephyr\dts\arm\st\g0\stm32g0.dtsi:34 */
			compatible = "arm,cortex-m0+";        /* in zephyr\dts\arm\st\g0\stm32g0.dtsi:35 */
			reg = < 0x0 >;                        /* in zephyr\dts\arm\st\g0\stm32g0.dtsi:36 */
			cpu-power-states = < &stop0 &stop1 >; /* in zephyr\dts\arm\st\g0\stm32g0.dtsi:37 */
		};

		/* node '/cpus/power-states' defined in zephyr\dts\arm\st\g0\stm32g0.dtsi:40 */
		power-states {

			/* node '/cpus/power-states/state0' defined in zephyr\dts\arm\st\g0\stm32g0.dtsi:41 */
			stop0: state0 {
				compatible = "zephyr,power-state";    /* in zephyr\dts\arm\st\g0\stm32g0.dtsi:42 */
				power-state-name = "suspend-to-idle"; /* in zephyr\dts\arm\st\g0\stm32g0.dtsi:43 */
				substate-id = < 0x1 >;                /* in zephyr\dts\arm\st\g0\stm32g0.dtsi:44 */
				min-residency-us = < 0x14 >;          /* in zephyr\dts\arm\st\g0\stm32g0.dtsi:45 */
				phandle = < 0x1c >;                   /* in zephyr\dts\arm\st\g0\stm32g0.dtsi:37 */
			};

			/* node '/cpus/power-states/state1' defined in zephyr\dts\arm\st\g0\stm32g0.dtsi:48 */
			stop1: state1 {
				compatible = "zephyr,power-state";    /* in zephyr\dts\arm\st\g0\stm32g0.dtsi:49 */
				power-state-name = "suspend-to-idle"; /* in zephyr\dts\arm\st\g0\stm32g0.dtsi:50 */
				substate-id = < 0x2 >;                /* in zephyr\dts\arm\st\g0\stm32g0.dtsi:51 */
				min-residency-us = < 0x64 >;          /* in zephyr\dts\arm\st\g0\stm32g0.dtsi:52 */
				phandle = < 0x1d >;                   /* in zephyr\dts\arm\st\g0\stm32g0.dtsi:37 */
			};
		};
	};

	/* node '/memory@20000000' defined in zephyr\dts\arm\st\g0\stm32g0.dtsi:57 */
	sram0: memory@20000000 {
		compatible = "mmio-sram";    /* in zephyr\dts\arm\st\g0\stm32g0.dtsi:58 */
		reg = < 0x20000000 0x9000 >; /* in zephyr\dts\arm\st\g0\stm32g071Xb.dtsi:13 */
	};

	/* node '/clocks' defined in zephyr\dts\arm\st\g0\stm32g0.dtsi:61 */
	clocks {

		/* node '/clocks/clk-hse' defined in zephyr\dts\arm\st\g0\stm32g0.dtsi:62 */
		clk_hse: clk-hse {
			#clock-cells = < 0x0 >;            /* in zephyr\dts\arm\st\g0\stm32g0.dtsi:63 */
			compatible = "st,stm32-hse-clock"; /* in zephyr\dts\arm\st\g0\stm32g0.dtsi:64 */
			status = "disabled";               /* in zephyr\dts\arm\st\g0\stm32g0.dtsi:65 */
		};

		/* node '/clocks/clk-hsi' defined in zephyr\dts\arm\st\g0\stm32g0.dtsi:68 */
		clk_hsi: clk-hsi {
			#clock-cells = < 0x0 >;              /* in zephyr\dts\arm\st\g0\stm32g0.dtsi:69 */
			compatible = "st,stm32g0-hsi-clock"; /* in zephyr\dts\arm\st\g0\stm32g0.dtsi:70 */
			hsi-div = < 0x1 >;                   /* in zephyr\dts\arm\st\g0\stm32g0.dtsi:71 */
			clock-frequency = < 0xf42400 >;      /* in zephyr\dts\arm\st\g0\stm32g0.dtsi:72 */
			status = "okay";                     /* in zephyr\boards\st\nucleo_g071rb\nucleo_g071rb.dts:60 */
			phandle = < 0x1e >;                  /* in zephyr\boards\st\nucleo_g071rb\nucleo_g071rb.dts:69 */
		};

		/* node '/clocks/clk-lse' defined in zephyr\dts\arm\st\g0\stm32g0.dtsi:76 */
		clk_lse: clk-lse {
			#clock-cells = < 0x0 >;            /* in zephyr\dts\arm\st\g0\stm32g0.dtsi:77 */
			compatible = "st,stm32-lse-clock"; /* in zephyr\dts\arm\st\g0\stm32g0.dtsi:78 */
			clock-frequency = < 0x8000 >;      /* in zephyr\dts\arm\st\g0\stm32g0.dtsi:79 */
			driving-capability = < 0x0 >;      /* in zephyr\dts\arm\st\g0\stm32g0.dtsi:80 */
			status = "disabled";               /* in zephyr\dts\arm\st\g0\stm32g0.dtsi:81 */
		};

		/* node '/clocks/clk-lsi' defined in zephyr\dts\arm\st\g0\stm32g0.dtsi:84 */
		clk_lsi: clk-lsi {
			#clock-cells = < 0x0 >;       /* in zephyr\dts\arm\st\g0\stm32g0.dtsi:85 */
			compatible = "fixed-clock";   /* in zephyr\dts\arm\st\g0\stm32g0.dtsi:86 */
			clock-frequency = < 0x7d00 >; /* in zephyr\dts\arm\st\g0\stm32g0.dtsi:87 */
			status = "okay";              /* in zephyr\boards\st\nucleo_g071rb\nucleo_g071rb.dts:56 */
		};

		/* node '/clocks/pll' defined in zephyr\dts\arm\st\g0\stm32g0.dtsi:91 */
		pll: pll {
			#clock-cells = < 0x0 >;              /* in zephyr\dts\arm\st\g0\stm32g0.dtsi:92 */
			compatible = "st,stm32g0-pll-clock"; /* in zephyr\dts\arm\st\g0\stm32g0.dtsi:93 */
			div-m = < 0x1 >;                     /* in zephyr\boards\st\nucleo_g071rb\nucleo_g071rb.dts:64 */
			mul-n = < 0x8 >;                     /* in zephyr\boards\st\nucleo_g071rb\nucleo_g071rb.dts:65 */
			div-p = < 0x2 >;                     /* in zephyr\boards\st\nucleo_g071rb\nucleo_g071rb.dts:66 */
			div-q = < 0x2 >;                     /* in zephyr\boards\st\nucleo_g071rb\nucleo_g071rb.dts:67 */
			div-r = < 0x2 >;                     /* in zephyr\boards\st\nucleo_g071rb\nucleo_g071rb.dts:68 */
			clocks = < &clk_hsi >;               /* in zephyr\boards\st\nucleo_g071rb\nucleo_g071rb.dts:69 */
			status = "okay";                     /* in zephyr\boards\st\nucleo_g071rb\nucleo_g071rb.dts:70 */
			phandle = < 0x3 >;                   /* in zephyr\boards\st\nucleo_g071rb\nucleo_g071rb.dts:74 */
		};
	};

	/* node '/mcos' defined in zephyr\dts\arm\st\g0\stm32g0.dtsi:98 */
	mcos {

		/* node '/mcos/mco1' defined in zephyr\dts\arm\st\g0\stm32g0.dtsi:99 */
		mco1: mco1 {
			compatible = "st,stm32-clock-mco"; /* in zephyr\dts\arm\st\g0\stm32g0.dtsi:100 */
			status = "disabled";               /* in zephyr\dts\arm\st\g0\stm32g0.dtsi:101 */
		};

		/* node '/mcos/mco2' defined in zephyr\dts\arm\st\g0\stm32g0.dtsi:104 */
		mco2: mco2 {
			compatible = "st,stm32-clock-mco"; /* in zephyr\dts\arm\st\g0\stm32g0.dtsi:105 */
			status = "disabled";               /* in zephyr\dts\arm\st\g0\stm32g0.dtsi:106 */
		};
	};

	/* node '/dietemp' defined in zephyr\dts\arm\st\g0\stm32g0.dtsi:514 */
	die_temp: dietemp {
		compatible = "st,stm32-temp-cal"; /* in zephyr\dts\arm\st\g0\stm32g0.dtsi:515 */
		ts-cal1-addr = < 0x1fff75a8 >;    /* in zephyr\dts\arm\st\g0\stm32g0.dtsi:516 */
		ts-cal2-addr = < 0x1fff75ca >;    /* in zephyr\dts\arm\st\g0\stm32g0.dtsi:517 */
		ts-cal1-temp = < 0x1e >;          /* in zephyr\dts\arm\st\g0\stm32g0.dtsi:518 */
		ts-cal2-temp = < 0x82 >;          /* in zephyr\dts\arm\st\g0\stm32g0.dtsi:519 */
		ts-cal-vrefanalog = < 0xbb8 >;    /* in zephyr\dts\arm\st\g0\stm32g0.dtsi:520 */
		io-channels = < &adc1 0xc >;      /* in zephyr\dts\arm\st\g0\stm32g0.dtsi:521 */
		status = "okay";                  /* in zephyr\boards\st\nucleo_g071rb\nucleo_g071rb.dts:165 */
	};

	/* node '/vref' defined in zephyr\dts\arm\st\g0\stm32g0.dtsi:525 */
	vref: vref {
		compatible = "st,stm32-vref";      /* in zephyr\dts\arm\st\g0\stm32g0.dtsi:526 */
		vrefint-cal-addr = < 0x1fff75aa >; /* in zephyr\dts\arm\st\g0\stm32g0.dtsi:527 */
		vrefint-cal-mv = < 0xbb8 >;        /* in zephyr\dts\arm\st\g0\stm32g0.dtsi:528 */
		io-channels = < &adc1 0xd >;       /* in zephyr\dts\arm\st\g0\stm32g0.dtsi:529 */
		status = "okay";                   /* in zephyr\boards\st\nucleo_g071rb\nucleo_g071rb.dts:189 */
	};

	/* node '/vbat' defined in zephyr\dts\arm\st\g0\stm32g0.dtsi:533 */
	vbat: vbat {
		compatible = "st,stm32-vbat"; /* in zephyr\dts\arm\st\g0\stm32g0.dtsi:534 */
		ratio = < 0x3 >;              /* in zephyr\dts\arm\st\g0\stm32g0.dtsi:535 */
		io-channels = < &adc1 0xe >;  /* in zephyr\dts\arm\st\g0\stm32g0.dtsi:536 */
		status = "okay";              /* in zephyr\boards\st\nucleo_g071rb\nucleo_g071rb.dts:193 */
	};

	/* node '/smbus1' defined in zephyr\dts\arm\st\g0\stm32g0.dtsi:540 */
	smbus1: smbus1 {
		compatible = "st,stm32-smbus"; /* in zephyr\dts\arm\st\g0\stm32g0.dtsi:541 */
		#address-cells = < 0x1 >;      /* in zephyr\dts\arm\st\g0\stm32g0.dtsi:542 */
		#size-cells = < 0x0 >;         /* in zephyr\dts\arm\st\g0\stm32g0.dtsi:543 */
		i2c = < &i2c1 >;               /* in zephyr\dts\arm\st\g0\stm32g0.dtsi:544 */
		status = "disabled";           /* in zephyr\dts\arm\st\g0\stm32g0.dtsi:545 */
	};

	/* node '/smbus2' defined in zephyr\dts\arm\st\g0\stm32g0.dtsi:548 */
	smbus2: smbus2 {
		compatible = "st,stm32-smbus"; /* in zephyr\dts\arm\st\g0\stm32g0.dtsi:549 */
		#address-cells = < 0x1 >;      /* in zephyr\dts\arm\st\g0\stm32g0.dtsi:550 */
		#size-cells = < 0x0 >;         /* in zephyr\dts\arm\st\g0\stm32g0.dtsi:551 */
		i2c = < &i2c2 >;               /* in zephyr\dts\arm\st\g0\stm32g0.dtsi:552 */
		status = "disabled";           /* in zephyr\dts\arm\st\g0\stm32g0.dtsi:553 */
	};

	/* node '/connector' defined in zephyr\boards\st\nucleo_g071rb\arduino_r3_connector.dtsi:10 */
	arduino_header: connector {
		compatible = "arduino-header-r3";          /* in zephyr\boards\st\nucleo_g071rb\arduino_r3_connector.dtsi:11 */
		#gpio-cells = < 0x2 >;                     /* in zephyr\boards\st\nucleo_g071rb\arduino_r3_connector.dtsi:12 */
		gpio-map-mask = < 0xffffffff 0xffffffc0 >; /* in zephyr\boards\st\nucleo_g071rb\arduino_r3_connector.dtsi:13 */
		gpio-map-pass-thru = < 0x0 0x3f >;         /* in zephyr\boards\st\nucleo_g071rb\arduino_r3_connector.dtsi:14 */
		gpio-map = < 0x0 0x0 &gpioa 0x0 0x0 >,
		           < 0x1 0x0 &gpioa 0x1 0x0 >,
		           < 0x2 0x0 &gpioa 0x4 0x0 >,
		           < 0x3 0x0 &gpiob 0x1 0x0 >,
		           < 0x4 0x0 &gpiob 0xb 0x0 >,
		           < 0x5 0x0 &gpiob 0xc 0x0 >,
		           < 0x6 0x0 &gpioc 0x5 0x0 >,
		           < 0x7 0x0 &gpioc 0x4 0x0 >,
		           < 0x8 0x0 &gpioa 0xa 0x0 >,
		           < 0x9 0x0 &gpiob 0x3 0x0 >,
		           < 0xa 0x0 &gpiob 0x5 0x0 >,
		           < 0xb 0x0 &gpiob 0x4 0x0 >,
		           < 0xc 0x0 &gpiob 0xe 0x0 >,
		           < 0xd 0x0 &gpioa 0x8 0x0 >,
		           < 0xe 0x0 &gpioa 0x9 0x0 >,
		           < 0xf 0x0 &gpioc 0x7 0x0 >,
		           < 0x10 0x0 &gpiob 0x0 0x0 >,
		           < 0x11 0x0 &gpioa 0x7 0x0 >,
		           < 0x12 0x0 &gpioa 0x6 0x0 >,
		           < 0x13 0x0 &gpioa 0x5 0x0 >,
		           < 0x14 0x0 &gpiob 0x9 0x0 >,
		           < 0x15 0x0 &gpiob 0x8 0x0 >;    /* in zephyr\boards\st\nucleo_g071rb\arduino_r3_connector.dtsi:15 */
	};

	/* node '/st-morpho-header' defined in zephyr\boards\st\nucleo_g071rb\st_morpho_connector.dtsi:10 */
	st_morpho_header: st-morpho-header {
		compatible = "st-morpho-header";        /* in zephyr\boards\st\nucleo_g071rb\st_morpho_connector.dtsi:11 */
		#gpio-cells = < 0x2 >;                  /* in zephyr\boards\st\nucleo_g071rb\st_morpho_connector.dtsi:12 */
		gpio-map-mask = < 0xff 0x0 >;           /* in zephyr\boards\st\nucleo_g071rb\st_morpho_connector.dtsi:13 */
		gpio-map-pass-thru = < 0x0 0x7f >;      /* in zephyr\boards\st\nucleo_g071rb\st_morpho_connector.dtsi:14 */
		gpio-map = < 0x0 0x0 &gpioc 0xa 0x0 >,
		           < 0x1 0x0 &gpioc 0xb 0x0 >,
		           < 0x2 0x0 &gpioc 0xc 0x0 >,
		           < 0x3 0x0 &gpiod 0x2 0x0 >,
		           < 0x6 0x0 &gpioa 0xe 0x0 >,
		           < 0x8 0x0 &gpiod 0x0 0x0 >,
		           < 0x9 0x0 &gpiod 0x1 0x0 >,
		           < 0xa 0x0 &gpiod 0x3 0x0 >,
		           < 0xc 0x0 &gpioa 0xd 0x0 >,
		           < 0xe 0x0 &gpiod 0x4 0x0 >,
		           < 0x10 0x0 &gpioa 0xf 0x0 >,
		           < 0x14 0x0 &gpiob 0x7 0x0 >,
		           < 0x16 0x0 &gpioc 0xd 0x0 >,
		           < 0x18 0x0 &gpioc 0xe 0x0 >,
		           < 0x19 0x0 &gpiod 0x5 0x0 >,
		           < 0x1a 0x0 &gpioc 0xf 0x0 >,
		           < 0x1b 0x0 &gpioa 0x0 0x0 >,
		           < 0x1c 0x0 &gpiof 0x0 0x0 >,
		           < 0x1d 0x0 &gpioa 0x1 0x0 >,
		           < 0x1e 0x0 &gpiof 0x1 0x0 >,
		           < 0x1f 0x0 &gpioa 0x4 0x0 >,
		           < 0x21 0x0 &gpiob 0x1 0x0 >,
		           < 0x22 0x0 &gpioc 0x2 0x0 >,
		           < 0x23 0x0 &gpiob 0xb 0x0 >,
		           < 0x24 0x0 &gpioc 0x3 0x0 >,
		           < 0x25 0x0 &gpiob 0xc 0x0 >,
		           < 0x48 0x0 &gpioc 0x9 0x0 >,
		           < 0x49 0x0 &gpioc 0x8 0x0 >,
		           < 0x4a 0x0 &gpiob 0x8 0x0 >,
		           < 0x4b 0x0 &gpioc 0x6 0x0 >,
		           < 0x4c 0x0 &gpiob 0x9 0x0 >,
		           < 0x4d 0x0 &gpioa 0x3 0x0 >,
		           < 0x51 0x0 &gpiod 0x6 0x0 >,
		           < 0x52 0x0 &gpioa 0x5 0x0 >,
		           < 0x53 0x0 &gpioa 0xc 0x0 >,
		           < 0x54 0x0 &gpioa 0x6 0x0 >,
		           < 0x55 0x0 &gpioa 0xb 0x0 >,
		           < 0x56 0x0 &gpioa 0x7 0x0 >,
		           < 0x57 0x0 &gpioc 0x1 0x0 >,
		           < 0x58 0x0 &gpiob 0x0 0x0 >,
		           < 0x59 0x0 &gpioc 0x0 0x0 >,
		           < 0x5a 0x0 &gpioc 0x7 0x0 >,
		           < 0x5c 0x0 &gpioa 0x9 0x0 >,
		           < 0x5d 0x0 &gpiob 0x2 0x0 >,
		           < 0x5e 0x0 &gpioa 0x8 0x0 >,
		           < 0x5f 0x0 &gpiob 0x6 0x0 >,
		           < 0x60 0x0 &gpiob 0xe 0x0 >,
		           < 0x61 0x0 &gpiob 0xf 0x0 >,
		           < 0x62 0x0 &gpiob 0x4 0x0 >,
		           < 0x63 0x0 &gpiob 0xa 0x0 >,
		           < 0x64 0x0 &gpiob 0x5 0x0 >,
		           < 0x65 0x0 &gpiob 0xd 0x0 >,
		           < 0x66 0x0 &gpiob 0x3 0x0 >,
		           < 0x68 0x0 &gpioa 0xa 0x0 >,
		           < 0x69 0x0 &gpioa 0x2 0x0 >,
		           < 0x6a 0x0 &gpioc 0x4 0x0 >,
		           < 0x6b 0x0 &gpiod 0x8 0x0 >,
		           < 0x6c 0x0 &gpioc 0x5 0x0 >,
		           < 0x6d 0x0 &gpiod 0x9 0x0 >; /* in zephyr\boards\st\nucleo_g071rb\st_morpho_connector.dtsi:15 */
	};

	/* node '/leds' defined in zephyr\boards\st\nucleo_g071rb\nucleo_g071rb.dts:26 */
	leds: leds {
		compatible = "gpio-leds"; /* in zephyr\boards\st\nucleo_g071rb\nucleo_g071rb.dts:27 */

		/* node '/leds/led_4' defined in zephyr\boards\st\nucleo_g071rb\nucleo_g071rb.dts:29 */
		green_led_1: led_4 {
			gpios = < &gpioa 0x5 0x0 >; /* in zephyr\boards\st\nucleo_g071rb\nucleo_g071rb.dts:30 */
			label = "User LD4";         /* in zephyr\boards\st\nucleo_g071rb\nucleo_g071rb.dts:31 */
		};
	};

	/* node '/gpio_keys' defined in zephyr\boards\st\nucleo_g071rb\nucleo_g071rb.dts:35 */
	gpio_keys {
		compatible = "gpio-keys"; /* in zephyr\boards\st\nucleo_g071rb\nucleo_g071rb.dts:36 */

		/* node '/gpio_keys/button' defined in zephyr\boards\st\nucleo_g071rb\nucleo_g071rb.dts:38 */
		user_button: button {
			label = "User";             /* in zephyr\boards\st\nucleo_g071rb\nucleo_g071rb.dts:39 */
			gpios = < &gpioc 0xd 0x1 >; /* in zephyr\boards\st\nucleo_g071rb\nucleo_g071rb.dts:40 */
			zephyr,code = < 0xb >;      /* in zephyr\boards\st\nucleo_g071rb\nucleo_g071rb.dts:41 */
		};
	};
};
